VERSION "v0.0.5"

NS_ :

BS_:

BU_: LOCO_PLC Screen DCDC1 CVC Telematics PDM1

BO_ 2147545100 Debug_C: 8 CVC
 SG_ debug_C_plc_msg1F_count m31 : 48|16@1+ (1,0) [0|65535] "0"  Telematics
 SG_ debug_C_plc_msg1E_count m30 : 48|16@1+ (1,0) [0|65535] "0"  Telematics
 SG_ debug_C_plc_msg1D_count m29 : 48|16@1+ (1,0) [0|65535] "0"  Telematics
 SG_ debug_C_plc_msg1C_count m28 : 48|16@1+ (1,0) [0|65535] "0"  Telematics
 SG_ debug_C_plc_msg1B_count m27 : 48|16@1+ (1,0) [0|65535] "0"  Telematics
 SG_ debug_C_plc_msg1A_count m26 : 48|16@1+ (1,0) [0|65535] "0"  Telematics
 SG_ debug_C_plc_msg19_count m25 : 48|16@1+ (1,0) [0|65535] "0"  Telematics
 SG_ debug_C_plc_msg18_count m24 : 48|16@1+ (1,0) [0|65535] "0"  Telematics
 SG_ debug_C_plc_msg17_count m23 : 48|16@1+ (1,0) [0|65535] "0"  Telematics
 SG_ debug_C_plc_msg16_count m22 : 48|16@1+ (1,0) [0|65535] "0"  Telematics
 SG_ debug_C_plc_msg15_count m21 : 48|16@1+ (1,0) [0|65535] "0"  Telematics
 SG_ debug_C_plc_msg14_count m20 : 48|16@1+ (1,0) [0|65535] "0"  Telematics
 SG_ debug_C_plc_msg13_count m19 : 48|16@1+ (1,0) [0|65535] "0"  Telematics
 SG_ debug_C_plc_msg12_count m18 : 48|16@1+ (1,0) [0|65535] "0"  Telematics
 SG_ debug_C_plc_msg11_count m17 : 48|16@1+ (1,0) [0|65535] "0"  Telematics
 SG_ debug_C_plc_msg10_count m16 : 48|16@1+ (1,0) [0|65535] "0"  Telematics
 SG_ debug_C_plc_msg0F_count m15 : 48|16@1+ (1,0) [0|65535] "0"  Telematics
 SG_ debug_C_plc_msg0E_count m14 : 48|16@1+ (1,0) [0|65535] "0"  Telematics
 SG_ debug_C_plc_msg0D_count m13 : 48|16@1+ (1,0) [0|65535] "0"  Telematics
 SG_ debug_C_plc_msg0C_count m12 : 48|16@1+ (1,0) [0|65535] "0"  Telematics
 SG_ debug_C_plc_msg0B_count m11 : 48|16@1+ (1,0) [0|65535] "0"  Telematics
 SG_ debug_C_plc_msg0A_count m10 : 48|16@1+ (1,0) [0|65535] "0"  Telematics
 SG_ debug_C_plc_msg09_count m9 : 48|16@1+ (1,0) [0|65535] "0"  Telematics
 SG_ debug_C_plc_msg08_count m8 : 48|16@1+ (1,0) [0|65535] "0"  Telematics
 SG_ debug_C_plc_msg07_count m7 : 48|16@1+ (1,0) [0|65535] "0"  Telematics
 SG_ debug_C_plc_msg06_count m6 : 48|16@1+ (1,0) [0|65535] "0"  Telematics
 SG_ debug_C_plc_msg05_count m5 : 48|16@1+ (1,0) [0|65535] "0"  Telematics
 SG_ debug_C_plc_msg04_count m4 : 48|16@1+ (1,0) [0|65535] "0"  Telematics
 SG_ debug_C_plc_msg03_count m3 : 48|16@1+ (1,0) [0|65535] "0"  Telematics
 SG_ debug_C_plc_msg02_count m2 : 48|16@1+ (1,0) [0|65535] "0"  Telematics
 SG_ debug_C_plc_msg01_count m1 : 48|16@1+ (1,0) [0|65535] "0"  Telematics
 SG_ debug_C_plc_msg00_count m0 : 48|16@1+ (1,0) [0|65535] "0"  Telematics
 SG_ debug_C_plc_msg_mult M : 0|8@1+ (1,0) [0|255] "0"  Telematics

BO_ 2147545099 Debug_B: 8 CVC
 SG_ debug_B_Voltage_Sensor : 0|16@1+ (0.01,0) [0|600] "V"  LOCO_PLC

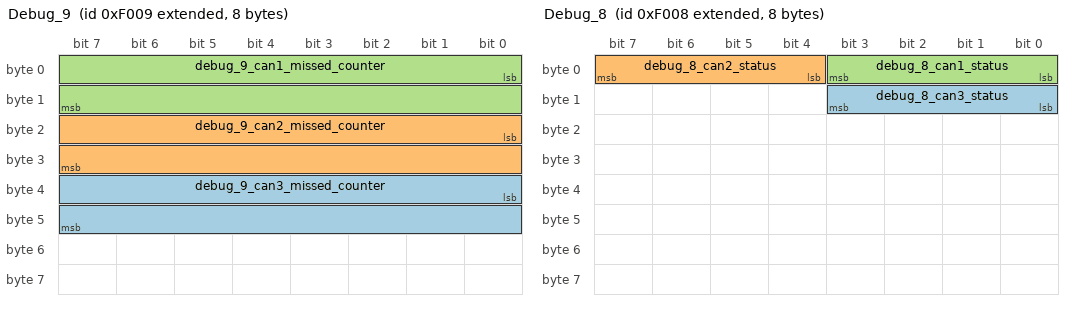
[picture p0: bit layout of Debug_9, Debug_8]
BO_ 2147545097 Debug_9: 8 CVC
 SG_ debug_9_can3_missed_counter : 32|16@1+ (1,0) [0|65535] ""  Telematics
 SG_ debug_9_can2_missed_counter : 16|16@1+ (1,0) [0|65535] ""  Telematics
 SG_ debug_9_can1_missed_counter : 0|16@1+ (1,0) [0|65535] ""  Telematics

BO_ 2147545096 Debug_8: 8 CVC
 SG_ debug_8_can3_status : 8|4@1+ (1,0) [0|15] ""  Telematics
 SG_ debug_8_can2_status : 4|4@1+ (1,0) [0|15] ""  Telematics
 SG_ debug_8_can1_status : 0|4@1+ (1,0) [0|15] ""  Telematics

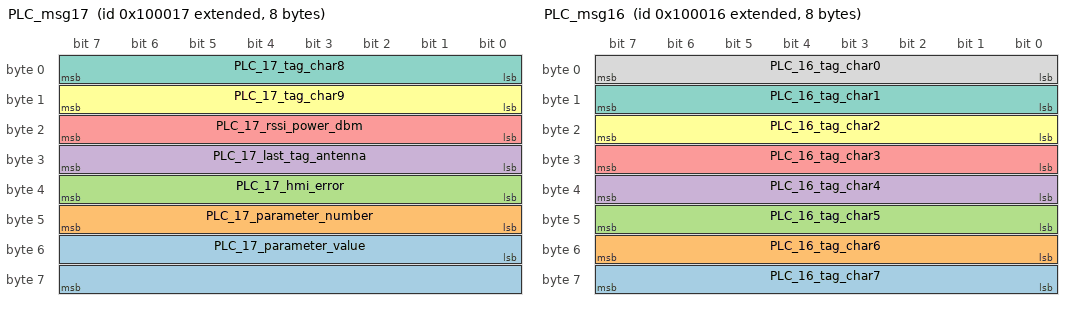
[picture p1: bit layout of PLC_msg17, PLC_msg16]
BO_ 2148532247 PLC_msg17: 8 LOCO_PLC
 SG_ PLC_17_parameter_value : 48|16@1+ (1,0) [0|255] ""  CVC
 SG_ PLC_17_parameter_number : 40|8@1+ (1,0) [0|255] ""  CVC
 SG_ PLC_17_hmi_error : 32|8@1+ (1,0) [0|255] ""  CVC
 SG_ PLC_17_last_tag_antenna : 24|8@1+ (1,0) [0|255] ""  CVC
 SG_ PLC_17_rssi_power_dbm : 16|8@1+ (1,0) [0|255] "dBm"  CVC
 SG_ PLC_17_tag_char9 : 8|8@1+ (1,0) [0|255] ""  CVC
 SG_ PLC_17_tag_char8 : 0|8@1+ (1,0) [0|255] ""  CVC

BO_ 2148532246 PLC_msg16: 8 LOCO_PLC
 SG_ PLC_16_tag_char7 : 56|8@1+ (1,0) [0|255] ""  CVC
 SG_ PLC_16_tag_char6 : 48|8@1+ (1,0) [0|255] ""  CVC
 SG_ PLC_16_tag_char5 : 40|8@1+ (1,0) [0|255] ""  CVC
 SG_ PLC_16_tag_char4 : 32|8@1+ (1,0) [0|255] ""  CVC
 SG_ PLC_16_tag_char3 : 24|8@1+ (1,0) [0|255] ""  CVC
 SG_ PLC_16_tag_char2 : 16|8@1+ (1,0) [0|255] ""  CVC
 SG_ PLC_16_tag_char1 : 8|8@1+ (1,0) [0|255] ""  CVC
 SG_ PLC_16_tag_char0 : 0|8@1+ (1,0) [0|255] ""  CVC

BO_ 2148532245 PLC_msg15: 8 LOCO_PLC
 SG_ PLC_15_unused_63 : 63|1@1+ (1,0) [0|1] ""  CVC
 SG_ PLC_15_unused_62 : 62|1@1+ (1,0) [0|1] ""  CVC
 SG_ PLC_15_unused_61 : 61|1@1+ (1,0) [0|1] ""  CVC
 SG_ PLC_15_earth_leakage : 60|1@1+ (1,0) [0|1] ""  CVC
 SG_ PLC_15_alarm_vibration_gb2 : 59|1@1+ (1,0) [0|1] ""  CVC
 SG_ PLC_15_prealarm_vibration_gb2 : 58|1@1+ (1,0) [0|1] ""  CVC
 SG_ PLC_15_alarm_vibration_gb1 : 57|1@1+ (1,0) [0|1] ""  CVC
 SG_ PLC_15_prealarm_vibration_gb1 : 56|1@1+ (1,0) [0|1] ""  CVC
 SG_ PLC_15_unused_55 : 55|1@1+ (1,0) [0|1] ""  CVC
 SG_ PLC_15_unused_54 : 54|1@1+ (1,0) [0|1] ""  CVC
 SG_ PLC_15_drive_cont_aux2 : 53|1@1+ (1,0) [0|1] ""  CVC
 SG_ PLC_15_drive_cont_2 : 52|1@1+ (1,0) [0|1] ""  CVC
 SG_ PLC_15_precharge_2 : 51|1@1+ (1,0) [0|1] ""  CVC
 SG_ PLC_15_drive_cont_aux1 : 50|1@1+ (1,0) [0|1] ""  CVC
 SG_ PLC_15_drive_cont_1 : 49|1@1+ (1,0) [0|1] ""  CVC
 SG_ PLC_15_precharge_1 : 48|1@1+ (1,0) [0|1] ""  CVC
 SG_ PLC_15_unused_47 : 47|1@1+ (1,0) [0|1] ""  CVC
 SG_ PLC_15_unused_46 : 46|1@1+ (1,0) [0|1] ""  CVC
 SG_ PLC_15_unused_45 : 45|1@1+ (1,0) [0|1] ""  CVC
 SG_ PLC_15_unused_44 : 44|1@1+ (1,0) [0|1] ""  CVC
 SG_ PLC_15_parameter_pin_ok : 43|1@1+ (1,0) [0|1] ""  CVC
 SG_ PLC_15_page_parameters : 42|1@1+ (1,0) [0|1] ""  CVC
 SG_ PLC_15_tester_pin_ok : 41|1@1+ (1,0) [0|1] ""  CVC
 SG_ PLC_15_page_tester : 40|1@1+ (1,0) [0|1] ""  CVC
 SG_ PLC_15_unused_39 : 39|1@1+ (1,0) [0|1] ""  CVC
 SG_ PLC_15_unused_38 : 38|1@1+ (1,0) [0|1] ""  CVC
 SG_ PLC_15_unused_37 : 37|1@1+ (1,0) [0|1] ""  CVC
 SG_ PLC_15_unused_36 : 36|1@1+ (1,0) [0|1] ""  CVC
 SG_ PLC_15_high_power_mode : 35|1@1+ (1,0) [0|1] ""  CVC
 SG_ PLC_15_direction_locked : 34|1@1+ (1,0) [0|1] ""  CVC
 SG_ PLC_15_direction_outbyte : 33|1@1+ (1,0) [0|1] ""  CVC
 SG_ PLC_15_direction_inbyte : 32|1@1+ (1,0) [0|1] ""  CVC
 SG_ PLC_15_unused_31 : 31|1@1+ (1,0) [0|1] ""  CVC
 SG_ PLC_15_unused_30 : 30|1@1+ (1,0) [0|1] ""  CVC
 SG_ PLC_15_unused_29 : 29|1@1+ (1,0) [0|1] ""  CVC
 SG_ PLC_15_unused_28 : 28|1@1+ (1,0) [0|1] ""  CVC
 SG_ PLC_15_unused_27 : 27|1@1+ (1,0) [0|1] ""  CVC
 SG_ PLC_15_wifi_locked : 26|1@1+ (1,0) [0|1] ""  CVC
 SG_ PLC_15_remote_connected : 25|1@1+ (1,0) [0|1] ""  CVC
 SG_ PLC_15_tandem_connected : 24|1@1+ (1,0) [0|1] ""  CVC
 SG_ PLC_15_unused_23 : 23|1@1+ (1,0) [0|1] ""  CVC
 SG_ PLC_15_unused_22 : 22|1@1+ (1,0) [0|1] ""  CVC
 SG_ PLC_15_unused_21 : 21|1@1+ (1,0) [0|1] ""  CVC
 SG_ PLC_15_unused_20 : 20|1@1+ (1,0) [0|1] ""  CVC
 SG_ PLC_15_axlebox_4 : 19|1@1+ (1,0) [0|1] ""  CVC
 SG_ PLC_15_axlebox_3 : 18|1@1+ (1,0) [0|1] ""  CVC
 SG_ PLC_15_axlebox_2 : 17|1@1+ (1,0) [0|1] ""  CVC
 SG_ PLC_15_axlebox_1 : 16|1@1+ (1,0) [0|1] ""  CVC
 SG_ PLC_15_unused_15 : 15|1@1+ (1,0) [0|1] ""  CVC
 SG_ PLC_15_unused_14 : 14|1@1+ (1,0) [0|1] ""  CVC
 SG_ PLC_15_unused_13 : 13|1@1+ (1,0) [0|1] ""  CVC
 SG_ PLC_15_unused_12 : 12|1@1+ (1,0) [0|1] ""  CVC
 SG_ PLC_15_pb_train_in_motion : 11|1@1+ (1,0) [0|1] ""  CVC
 SG_ PLC_15_deadmans_as_serv_brake : 10|1@1+ (1,0) [0|1] ""  CVC
 SG_ PLC_15_bat_disconnect_moving : 9|1@1+ (1,0) [0|1] ""  CVC
 SG_ PLC_15_bat_disconnect_stationary : 8|1@1+ (1,0) [0|1] ""  CVC
 SG_ PLC_15_train_d : 7|1@1+ (1,0) [0|1] ""  CVC
 SG_ PLC_15_train_c : 6|1@1+ (1,0) [0|1] ""  CVC
 SG_ PLC_15_train_b : 5|1@1+ (1,0) [0|1] ""  CVC
 SG_ PLC_15_train_a : 4|1@1+ (1,0) [0|1] ""  CVC
 SG_ PLC_15_single : 3|1@1+ (1,0) [0|1] ""  CVC
 SG_ PLC_15_slave : 2|1@1+ (1,0) [0|1] ""  CVC
 SG_ PLC_15_master_no_plug : 1|1@1+ (1,0) [0|1] ""  CVC
 SG_ PLC_15_master : 0|1@1+ (1,0) [0|1] ""  CVC

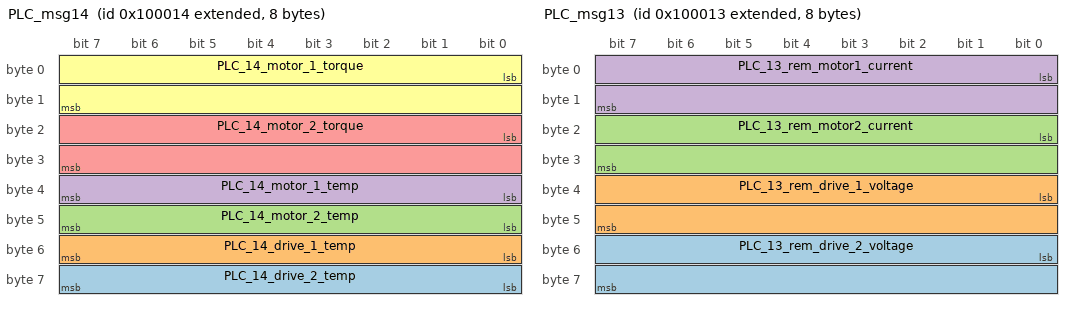
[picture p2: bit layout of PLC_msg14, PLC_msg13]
BO_ 2148532244 PLC_msg14: 8 LOCO_PLC
 SG_ PLC_14_drive_2_temp : 56|8@1+ (1,-40) [-40|210] "C"  CVC
 SG_ PLC_14_drive_1_temp : 48|8@1+ (1,-40) [-40|210] "C"  CVC
 SG_ PLC_14_motor_2_temp : 40|8@1+ (1,-40) [-40|210] "C"  CVC
 SG_ PLC_14_motor_1_temp : 32|8@1+ (1,-40) [-40|210] "C"  CVC
 SG_ PLC_14_motor_2_torque : 16|16@1+ (0.004,-125) [-125|132.02] "%"  CVC
 SG_ PLC_14_motor_1_torque : 0|16@1+ (0.004,-125) [-125|132.02] "%"  CVC

BO_ 2148532243 PLC_msg13: 8 LOCO_PLC
 SG_ PLC_13_rem_drive_2_voltage : 48|16@1+ (0.05,0) [0|3276.75] "V"  CVC
 SG_ PLC_13_rem_drive_1_voltage : 32|16@1+ (0.05,0) [0|3276.75] "V"  CVC
 SG_ PLC_13_rem_motor2_current : 16|16@1+ (0.05,-1600) [-1638.4|1638.35] "A"  CVC
 SG_ PLC_13_rem_motor1_current : 0|16@1+ (0.05,-1600) [-1638.4|1638.35] "A"  CVC

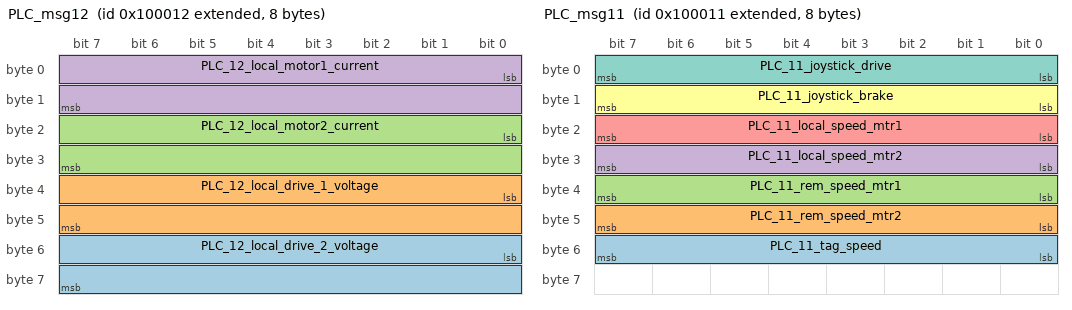
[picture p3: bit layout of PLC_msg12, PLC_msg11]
BO_ 2148532242 PLC_msg12: 8 LOCO_PLC
 SG_ PLC_12_local_drive_2_voltage : 48|16@1+ (0.05,0) [0|3276.75] "V"  CVC
 SG_ PLC_12_local_drive_1_voltage : 32|16@1+ (0.05,0) [0|3276.75] "V"  CVC
 SG_ PLC_12_local_motor2_current : 16|16@1+ (0.05,-1600) [-1638.4|1638.35] "A"  CVC
 SG_ PLC_12_local_motor1_current : 0|16@1+ (0.05,-1600) [-1638.4|1638.35] "A"  CVC

BO_ 2148532241 PLC_msg11: 8 LOCO_PLC
 SG_ PLC_11_tag_speed : 48|8@1+ (0.1,0) [0|25.5] "km/h"  CVC
 SG_ PLC_11_rem_speed_mtr2 : 40|8@1+ (0.1,0) [0|25.5] "km/h" Vector__XXX
 SG_ PLC_11_rem_speed_mtr1 : 32|8@1+ (0.1,0) [0|25.5] "km/h" Vector__XXX
 SG_ PLC_11_local_speed_mtr2 : 24|8@1+ (0.1,0) [0|25.5] "km/h"  CVC
 SG_ PLC_11_local_speed_mtr1 : 16|8@1+ (0.1,0) [0|25.5] "km/h"  CVC
 SG_ PLC_11_joystick_brake : 8|8@1+ (1,0) [0|255] "%"  CVC
 SG_ PLC_11_joystick_drive : 0|8@1+ (1,0) [0|255] "%"  CVC

BO_ 2148532240 PLC_msg10: 8 LOCO_PLC
 SG_ PLC_10_unused_7 : 56|8@1+ (1,0) [0|255] ""  CVC
 SG_ PLC_10_unused_6 : 54|2@1+ (1,0) [0|3] ""  CVC
 SG_ PLC_10_taillights_rear_rem : 53|1@1+ (1,0) [0|1] ""  CVC
 SG_ PLC_10_headlights_rear_rem : 52|1@1+ (1,0) [0|1] ""  CVC
 SG_ PLC_10_headlights_front_rem : 51|1@1+ (1,0) [0|1] ""  CVC
 SG_ PLC_10_taillights_rear_local : 50|1@1+ (1,0) [0|1] ""  CVC
 SG_ PLC_10_headlights_rear_local : 49|1@1+ (1,0) [0|1] ""  CVC
 SG_ PLC_10_headlights_front_local : 48|1@1+ (1,0) [0|1] ""  CVC
 SG_ PLC_10_unused_4 : 47|1@1+ (1,0) [0|1] ""  CVC
 SG_ PLC_10_remote_fire_pb : 46|1@1+ (1,0) [0|1] ""  CVC
 SG_ PLC_10_remote_fire_shutdown : 45|1@1+ (1,0) [0|1] ""  CVC
 SG_ PLC_10_local_fire_sys_shutdown : 44|1@1+ (1,0) [0|1] ""  CVC
 SG_ PLC_10_tandem_new_tag_braking : 43|1@1+ (1,0) [0|1] ""  CVC
 SG_ PLC_10_tandem_rem_batt_rtd : 42|1@1+ (1,0) [0|1] ""  CVC
 SG_ PLC_10_tandem_em_pb : 41|1@1+ (1,0) [0|1] ""  CVC
 SG_ PLC_10_tandem_esr : 40|1@1+ (1,0) [0|1] ""  CVC
 SG_ PLC_10_battery_ready_estop : 39|1@1+ (1,0) [0|1] ""  CVC
 SG_ PLC_10_tag_estop : 38|1@1+ (1,0) [0|1] ""  CVC
 SG_ PLC_10_overspeed : 37|1@1+ (1,0) [0|1] ""  CVC
 SG_ PLC_10_estop_console : 36|1@1+ (1,0) [0|1] ""  CVC
 SG_ PLC_10_estop_btn_remote : 35|1@1+ (1,0) [0|1] ""  CVC
 SG_ PLC_10_estop_relay_remote : 34|1@1+ (1,0) [0|1] ""  CVC
 SG_ PLC_10_estop_btn_local : 33|1@1+ (1,0) [0|1] ""  CVC
 SG_ PLC_10_estop_relay_local : 32|1@1+ (1,0) [0|1] ""  CVC
 SG_ PLC_10_unused_3 : 31|1@1+ (1,0) [0|1] ""  CVC
 SG_ PLC_10_slave : 30|1@1+ (1,0) [0|1] ""  CVC
 SG_ PLC_10_master_no_plug : 29|1@1+ (1,0) [0|1] ""  CVC
 SG_ PLC_10_master : 28|1@1+ (1,0) [0|1] ""  CVC
 SG_ PLC_10_seatbelt_remote : 27|1@1+ (1,0) [0|1] ""  CVC
 SG_ PLC_10_passenger_remote : 26|1@1+ (1,0) [0|1] ""  CVC
 SG_ PLC_10_seatbelt_local : 25|1@1+ (1,0) [0|1] ""  CVC
 SG_ PLC_10_driver_in_seat_local : 24|1@1+ (1,0) [0|1] ""  CVC
 SG_ PLC_10_pb_sw_in_motion : 23|1@1+ (1,0) [0|1] ""  CVC
 SG_ PLC_10_pb_2_remote : 22|1@1+ (1,0) [0|1] ""  CVC
 SG_ PLC_10_pb_1_remote : 21|1@1+ (1,0) [0|1] ""  CVC
 SG_ PLC_10_pb_relay_remote : 20|1@1+ (1,0) [0|1] ""  CVC
 SG_ PLC_10_pb_2_local : 19|1@1+ (1,0) [0|1] ""  CVC
 SG_ PLC_10_pb_1_local : 18|1@1+ (1,0) [0|1] ""  CVC
 SG_ PLC_10_pb_relay_local : 17|1@1+ (1,0) [0|1] ""  CVC
 SG_ PLC_10_pb_hold : 16|1@1+ (1,0) [0|1] ""  CVC
 SG_ PLC_10_explosives : 15|1@1+ (1,0) [0|1] ""  CVC
 SG_ PLC_10_key_full : 14|1@1+ (1,0) [0|1] ""  CVC
 SG_ PLC_10_key_neutral : 13|1@1+ (1,0) [0|1] ""  CVC
 SG_ PLC_10_key_semi : 12|1@1+ (1,0) [0|1] ""  CVC
 SG_ PLC_10_loco_rev : 11|1@1+ (1,0) [0|1] ""  CVC
 SG_ PLC_10_loco_fwd : 10|1@1+ (1,0) [0|1] ""  CVC
 SG_ PLC_10_rev_dir_sw : 9|1@1+ (1,0) [0|1] ""  CVC
 SG_ PLC_10_fwd_dir_sw : 8|1@1+ (1,0) [0|1] ""  CVC
 SG_ PLC_10_horn_console : 7|1@1+ (1,0) [0|1] ""  CVC
 SG_ PLC_10_horn_remote : 6|1@1+ (1,0) [0|1] ""  CVC
 SG_ PLC_10_horn_local : 5|1@1+ (1,0) [0|1] ""  CVC
 SG_ PLC_10_deadman_timer : 4|1@1+ (1,0) [0|1] ""  CVC
 SG_ PLC_10_deadman_trigger : 3|1@1+ (1,0) [0|1] ""  CVC
 SG_ PLC_10_neutral : 2|1@1+ (1,0) [0|1] ""  CVC
 SG_ PLC_10_brake : 1|1@1+ (1,0) [0|1] ""  CVC
 SG_ PLC_10_drive : 0|1@1+ (1,0) [0|1] ""  CVC

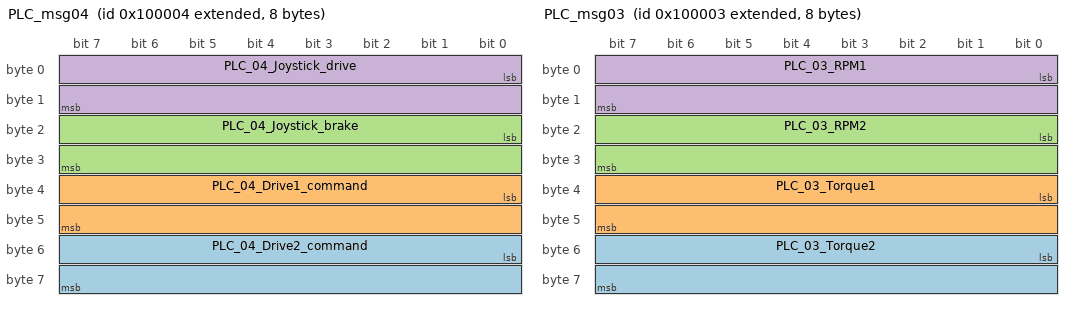
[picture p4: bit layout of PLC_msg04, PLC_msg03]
BO_ 2148532228 PLC_msg04: 8 LOCO_PLC
 SG_ PLC_04_Drive2_command : 48|16@1+ (0.08,-2500) [-2500|2742.8] "Nm"  CVC
 SG_ PLC_04_Drive1_command : 32|16@1+ (0.08,-2500) [-2500|2742.8] "Nm"  CVC
 SG_ PLC_04_Joystick_brake : 16|16@1+ (0.004,0) [0|262.14] "%"  CVC
 SG_ PLC_04_Joystick_drive : 0|16@1+ (0.004,0) [0|262.14] "%"  CVC

BO_ 2148532227 PLC_msg03: 8 LOCO_PLC
 SG_ PLC_03_Torque2 : 48|16@1+ (0.08,-2500) [-2500|2742.8] "Nm"  CVC
 SG_ PLC_03_Torque1 : 32|16@1+ (0.08,-2500) [-2500|2742.8] "Nm"  CVC
 SG_ PLC_03_RPM2 : 16|16@1+ (0.072,-2250) [-2250|2468.52] "RPM"  CVC
 SG_ PLC_03_RPM1 : 0|16@1+ (0.072,-2250) [-2250|2468.52] "RPM"  CVC

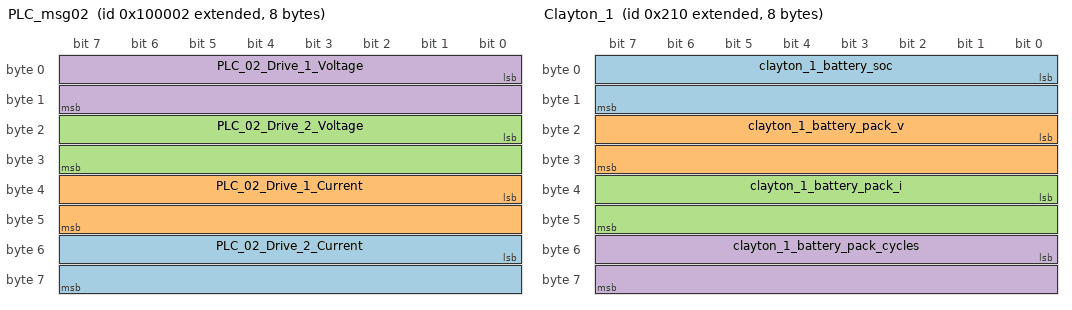
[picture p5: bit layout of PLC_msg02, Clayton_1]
BO_ 2148532226 PLC_msg02: 8 LOCO_PLC
 SG_ PLC_02_Drive_2_Current : 48|16@1+ (0.05,-1600) [-1600|1600] "A"  CVC
 SG_ PLC_02_Drive_1_Current : 32|16@1+ (0.05,-1600) [-1600|1600] "A"  CVC
 SG_ PLC_02_Drive_2_Voltage : 16|16@1+ (0.05,0) [0|3276.75] "V"  CVC
 SG_ PLC_02_Drive_1_Voltage : 0|16@1+ (0.05,0) [0|3276.75] "V"  CVC

BO_ 2148532225 PLC_msg01: 8 LOCO_PLC
 SG_ PLC_01_fire_suppression : 1|1@1+ (1,0) [0|1] ""  CVC
 SG_ PLC_01_earth_leakage : 0|1@1+ (1,0) [0|1] ""  CVC

BO_ 2148532224 PLC_msg00: 8 LOCO_PLC
 SG_ PLC_00_runtime : 0|32@1+ (0.000277777777777778,0) [0|1193046.47083333] "hr"  CVC
 SG_ PLC_00_distance : 32|32@1+ (2.77777777777778E-005,0) [0|119304.647083333] "km"  CVC

BO_ 2149273602 BMS_MSG2: 8 CVC
 SG_ BMS6_pack_soc m6 : 8|8@1+ (0.5,0) [0|127.5] "%"  LOCO_PLC
 SG_ BMS6_pack_inst_v m6 : 32|16@1+ (0.1,0) [0|6553.5] ""  LOCO_PLC
 SG_ BMS6_pack_cycles m6 : 48|16@1+ (1,0) [0|65535] ""  LOCO_PLC
 SG_ BMS6_pack_current m6 : 16|16@1- (0.1,0) [-3276.8|3276.7] "A"  LOCO_PLC
 SG_ BMS5_pack_soc m5 : 8|8@1+ (0.5,0) [0|127.5] "%"  LOCO_PLC
 SG_ BMS5_pack_inst_v m5 : 32|16@1+ (0.1,0) [0|6553.5] ""  LOCO_PLC
 SG_ BMS5_pack_cycles m5 : 48|16@1+ (1,0) [0|65535] ""  LOCO_PLC
 SG_ BMS5_pack_current m5 : 16|16@1- (0.1,0) [-3276.8|3276.7] "A"  LOCO_PLC
 SG_ BMS4_pack_soc m4 : 8|8@1+ (0.5,0) [0|127.5] "%"  LOCO_PLC
 SG_ BMS4_pack_inst_v m4 : 32|16@1+ (0.1,0) [0|6553.5] ""  LOCO_PLC
 SG_ BMS4_pack_cycles m4 : 48|16@1+ (1,0) [0|65535] ""  LOCO_PLC
 SG_ BMS4_pack_current m4 : 16|16@1- (0.1,0) [-3276.8|3276.7] "A"  LOCO_PLC
 SG_ BMS3_pack_inst_v m3 : 32|16@1+ (0.1,0) [0|6553.5] ""  LOCO_PLC
 SG_ BMS3_pack_cycles m3 : 48|16@1+ (1,0) [0|65535] ""  LOCO_PLC
 SG_ BMS3_pack_current m3 : 16|16@1- (0.1,0) [-3276.8|3276.7] "A"  LOCO_PLC
 SG_ BMS3_pack_soc m3 : 8|8@1+ (0.5,0) [0|127.5] "%"  LOCO_PLC
 SG_ BMS2_pack_inst_v m2 : 32|16@1+ (0.1,0) [0|6553.5] ""  LOCO_PLC
 SG_ BMS2_pack_cycles m2 : 48|16@1+ (1,0) [0|65535] ""  LOCO_PLC
 SG_ BMS2_pack_current m2 : 16|16@1- (0.1,0) [-3276.8|3276.7] "A"  LOCO_PLC
 SG_ BMS2_pack_soc m2 : 8|8@1+ (0.5,0) [0|127.5] "%"  LOCO_PLC
 SG_ BMS1_pack_soc m1 : 8|8@1+ (0.5,0) [0|127.5] "%"  LOCO_PLC
 SG_ BMS1_pack_inst_v m1 : 32|16@1+ (0.1,0) [0|6553.5] ""  LOCO_PLC
 SG_ BMS1_pack_cycles m1 : 48|16@1+ (1,0) [0|65535] ""  LOCO_PLC
 SG_ BMS1_pack_current m1 : 16|16@1- (0.1,0) [-3276.8|3276.7] "A"  LOCO_PLC
 SG_ BMS_MSG2_idx M : 0|8@1+ (1,0) [1|6] "ID"  LOCO_PLC

BO_ 2147484176 Clayton_1: 8 CVC
 SG_ clayton_1_battery_soc : 0|16@1+ (0.1,0) [0|6553.5] "%"  LOCO_PLC
 SG_ clayton_1_battery_pack_v : 16|16@1+ (0.1,0) [0|6553.5] "V"  LOCO_PLC
 SG_ clayton_1_battery_pack_i : 32|16@1- (0.1,0) [-3276.8|3276.7] "A"  LOCO_PLC
 SG_ clayton_1_battery_pack_cycles : 48|16@1+ (1,0) [0|65535] ""  LOCO_PLC

BO_ 2147484177 Clayton_2: 8 CVC
 SG_ clayton_2_unused_2 : 45|3@1+ (1,0) [0|1] ""  LOCO_PLC
 SG_ clayton_2_charger_coolant_level : 48|16@1+ (1,0) [0|65535] "%"  LOCO_PLC
 SG_ clayton_2_unused_1 : 39|1@1+ (1,0) [0|1] ""  LOCO_PLC
 SG_ clayton_2_limp_mode : 42|1@1+ (1,0) [0|1] ""  LOCO_PLC
 SG_ clayton_2_general_warning : 44|1@1+ (1,0) [0|1] ""  LOCO_PLC
 SG_ clayton_2_current_imbal_warning : 43|1@1+ (1,0) [0|1] ""  LOCO_PLC
 SG_ clayton_2_current_imbal_error : 38|1@1+ (1,0) [0|1] ""  LOCO_PLC
 SG_ clayton_2_coolant_low : 40|1@1+ (1,0) [0|1] ""  LOCO_PLC
 SG_ clayton_2_bms_warning : 41|1@1+ (1,0) [0|1] ""  LOCO_PLC
 SG_ clayton_2_pump_failure : 32|1@1+ (1,0) [0|1] ""  LOCO_PLC
 SG_ clayton_2_pump_current_warning : 30|1@1+ (1,0) [0|1] ""  LOCO_PLC
 SG_ clayton_2_fan_failure : 33|1@1+ (1,0) [0|1] ""  LOCO_PLC
 SG_ clayton_2_fan_current_warning : 31|1@1+ (1,0) [0|1] ""  LOCO_PLC
 SG_ clayton_2_critical_fault : 37|1@1+ (1,0) [0|1] ""  LOCO_PLC
 SG_ clayton_2_coolant_sensor_failure : 35|1@1+ (1,0) [0|1] ""  LOCO_PLC
 SG_ clayton_2_cell_delta_problem : 28|1@1+ (1,0) [0|1] ""  LOCO_PLC
 SG_ clayton_2_bms_temp_warning : 29|1@1+ (1,0) [0|1] ""  LOCO_PLC
 SG_ clayton_2_bms_error : 36|1@1+ (1,0) [0|1] ""  LOCO_PLC
 SG_ clayton_2_battery_under_temp : 34|1@1+ (1,0) [0|1] ""  LOCO_PLC
 SG_ clayton_2_warm_batt_temp : 25|1@1+ (1,0) [0|1] ""  LOCO_PLC
 SG_ clayton_2_uvp : 18|1@1+ (1,0) [0|1] ""  LOCO_PLC
 SG_ clayton_2_ucp : 20|1@1+ (1,0) [0|1] ""  LOCO_PLC
 SG_ clayton_2_subpacks_connected : 8|8@1+ (1,0) [0|255] ""  LOCO_PLC
 SG_ clayton_2_subpack_sync : 24|1@1+ (1,0) [0|1] ""  LOCO_PLC
 SG_ clayton_2_ovp : 17|1@1+ (1,0) [0|1] ""  LOCO_PLC
 SG_ clayton_2_ocp : 19|1@1+ (1,0) [0|1] ""  LOCO_PLC
 SG_ clayton_2_hvil_loop_broken : 16|1@1+ (1,0) [0|1] ""  LOCO_PLC
 SG_ clayton_2_hv_iso_fault : 21|1@1+ (1,0) [0|1] ""  LOCO_PLC
 SG_ clayton_2_estop_pushed : 27|1@1+ (1,0) [0|1] ""  LOCO_PLC
 SG_ clayton_2_contactor_failure : 22|1@1+ (1,0) [0|1] ""  LOCO_PLC
 SG_ clayton_2_battery_status : 0|8@1+ (1,0) [0|255] ""  LOCO_PLC
 SG_ clayton_2_battery_overtemp : 23|1@1+ (1,0) [0|1] ""  LOCO_PLC
 SG_ clayton_2_batt_too_cold : 26|1@1+ (1,0) [0|1] ""  LOCO_PLC

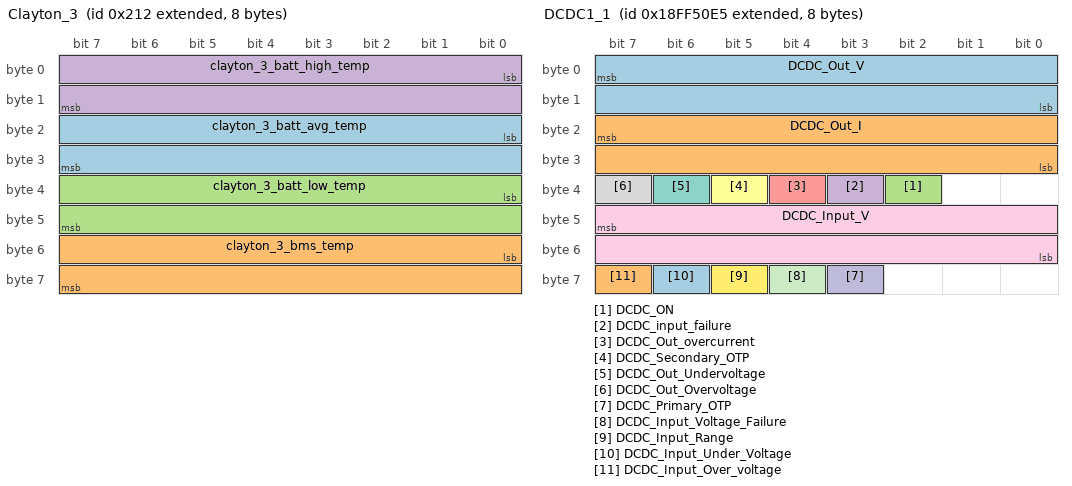
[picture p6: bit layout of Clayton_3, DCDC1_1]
BO_ 2147484178 Clayton_3: 8 CVC
 SG_ clayton_3_batt_avg_temp : 16|16@1- (1,0) [-32768|32767] "C"  LOCO_PLC
 SG_ clayton_3_bms_temp : 48|16@1- (1,0) [-32768|32767] "C"  LOCO_PLC
 SG_ clayton_3_batt_low_temp : 32|16@1- (1,0) [-32768|32767] "C"  LOCO_PLC
 SG_ clayton_3_batt_high_temp : 0|16@1- (1,0) [-32768|32767] "C"  LOCO_PLC

BO_ 2498698769 PDM_cmd: 8 CVC
 SG_ PDM_MULTIP_1 M : 0|8@1+ (1,0) [0|255] ""  PDM1
 SG_ PDM000_Output_Channel m0M : 8|8@1+ (1,0) [0|255] ""  PDM1
 SG_ PDM000_SS_Step_DO01 m1 : 16|8@1+ (1,0) [0|255] ""  PDM1
 SG_ PDM000_M_L_DO01 m1 : 24|8@1+ (1,0) [0|255] ""  PDM1
 SG_ PDM000_Loss_of_COMM_DO01 m1 : 32|8@1+ (1,0) [0|255] ""  PDM1
 SG_ PDM000_POR_command_DO01 m1 : 48|5@1- (6.25,0) [0|93] ""  PDM1
 SG_ PDM000_POR_En_DO01 m1 : 53|1@1+ (1,0) [0|1] ""  PDM1
 SG_ PDM000_Command_type_DO01 m1 : 54|1@1+ (1,0) [0|1] ""  PDM1
 SG_ PDM000_Motor_braking_DO01 m1 : 55|1@1+ (1,0) [0|1] ""  PDM1
 SG_ PDM000_LSC_DO01 m1 : 56|4@1+ (1,0) [0|15] ""  PDM1
 SG_ PDM000_Calib_time_DO01 m1 : 60|2@1+ (1,0) [0|3] ""  PDM1
 SG_ PDM000_Response_DO01 m1 : 62|2@1+ (1,0) [0|3] ""  PDM1
 SG_ PDM000_SS_Step_DO02 m2 : 16|8@1+ (1,0) [0|255] ""  PDM1
 SG_ PDM000_M_L_DO02 m2 : 24|8@1+ (1,0) [0|255] ""  PDM1
 SG_ PDM000_Loss_of_COMM_DO02 m2 : 32|8@1+ (1,0) [0|255] ""  PDM1
 SG_ PDM000_POR_command_DO02 m2 : 48|5@1- (6.25,0) [0|93] ""  PDM1
 SG_ PDM000_POR_En_DO02 m2 : 53|1@1+ (1,0) [0|1] ""  PDM1
 SG_ PDM000_Command_type_DO02 m2 : 54|1@1+ (1,0) [0|1] ""  PDM1
 SG_ PDM000_Motor_braking_DO02 m2 : 55|1@1+ (1,0) [0|1] ""  PDM1
 SG_ PDM000_LSC_DO02 m2 : 56|4@1+ (1,0) [0|15] ""  PDM1
 SG_ PDM000_Calib_time_DO02 m2 : 60|2@1+ (1,0) [0|3] ""  PDM1
 SG_ PDM000_Response_DO02 m2 : 62|2@1+ (1,0) [0|3] ""  PDM1
 SG_ PDM000_SS_Step_DO03 m3 : 16|8@1+ (1,0) [0|255] ""  PDM1
 SG_ PDM000_M_L_DO03 m3 : 24|8@1+ (1,0) [0|255] ""  PDM1
 SG_ PDM000_Loss_of_COMM_DO03 m3 : 32|8@1+ (1,0) [0|255] ""  PDM1
 SG_ PDM000_POR_command_DO03 m3 : 48|5@1- (6.25,0) [0|93] ""  PDM1
 SG_ PDM000_POR_En_DO03 m3 : 53|1@1+ (1,0) [0|1] ""  PDM1
 SG_ PDM000_Command_type_DO03 m3 : 54|1@1+ (1,0) [0|1] ""  PDM1
 SG_ PDM000_Motor_braking_DO03 m3 : 55|1@1+ (1,0) [0|1] ""  PDM1
 SG_ PDM000_LSC_DO03 m3 : 56|4@1+ (1,0) [0|15] ""  PDM1
 SG_ PDM000_Calib_time_DO03 m3 : 60|2@1+ (1,0) [0|3] ""  PDM1
 SG_ PDM000_Response_DO03 m3 : 62|2@1+ (1,0) [0|3] ""  PDM1
 SG_ PDM000_SS_Step_DO04 m4 : 16|8@1+ (1,0) [0|255] ""  PDM1
 SG_ PDM000_M_L_DO04 m4 : 24|8@1+ (1,0) [0|255] ""  PDM1
 SG_ PDM000_Loss_of_COMM_DO04 m4 : 32|8@1+ (1,0) [0|255] ""  PDM1
 SG_ PDM000_POR_command_DO04 m4 : 48|5@1- (6.25,0) [0|93] ""  PDM1
 SG_ PDM000_POR_En_DO04 m4 : 53|1@1+ (1,0) [0|1] ""  PDM1
 SG_ PDM000_Command_type_DO04 m4 : 54|1@1+ (1,0) [0|1] ""  PDM1
 SG_ PDM000_Motor_braking_DO04 m4 : 55|1@1+ (1,0) [0|1] ""  PDM1
 SG_ PDM000_LSC_DO04 m4 : 56|4@1+ (1,0) [0|15] ""  PDM1
 SG_ PDM000_Calib_time_DO04 m4 : 60|2@1+ (1,0) [0|3] ""  PDM1
 SG_ PDM000_Response_DO04 m4 : 62|2@1+ (1,0) [0|3] ""  PDM1
 SG_ PDM000_SS_Step_DO05 m5 : 16|8@1+ (1,0) [0|255] ""  PDM1
 SG_ PDM000_M_L_DO05 m5 : 24|8@1+ (1,0) [0|255] ""  PDM1
 SG_ PDM000_Loss_of_COMM_DO05 m5 : 32|8@1+ (1,0) [0|255] ""  PDM1
 SG_ PDM000_POR_command_DO05 m5 : 48|5@1- (6.25,0) [0|93] ""  PDM1
 SG_ PDM000_POR_En_DO05 m5 : 53|1@1+ (1,0) [0|1] ""  PDM1
 SG_ PDM000_Command_type_DO05 m5 : 54|1@1+ (1,0) [0|1] ""  PDM1
 SG_ PDM000_Motor_braking_DO05 m5 : 55|1@1+ (1,0) [0|1] ""  PDM1
 SG_ PDM000_LSC_DO05 m5 : 56|4@1+ (1,0) [0|15] ""  PDM1
 SG_ PDM000_Calib_time_DO05 m5 : 60|2@1+ (1,0) [0|3] ""  PDM1
 SG_ PDM000_Response_DO05 m5 : 62|2@1+ (1,0) [0|3] ""  PDM1
 SG_ PDM000_SS_Step_DO06 m6 : 16|8@1+ (1,0) [0|255] ""  PDM1
 SG_ PDM000_M_L_DO06 m6 : 24|8@1+ (1,0) [0|255] ""  PDM1
 SG_ PDM000_Loss_of_COMM_DO06 m6 : 32|8@1+ (1,0) [0|255] ""  PDM1
 SG_ PDM000_POR_command_DO06 m6 : 48|5@1- (6.25,0) [0|93] ""  PDM1
 SG_ PDM000_POR_En_DO06 m6 : 53|1@1+ (1,0) [0|1] ""  PDM1
 SG_ PDM000_Command_type_DO06 m6 : 54|1@1+ (1,0) [0|1] ""  PDM1
 SG_ PDM000_Motor_braking_DO06 m6 : 55|1@1+ (1,0) [0|1] ""  PDM1
 SG_ PDM000_LSC_DO06 m6 : 56|4@1+ (1,0) [0|15] ""  PDM1
 SG_ PDM000_Calib_time_DO06 m6 : 60|2@1+ (1,0) [0|3] ""  PDM1
 SG_ PDM000_Response_DO06 m6 : 62|2@1+ (1,0) [0|3] ""  PDM1
 SG_ PDM000_SS_Step_DO07 m7 : 16|8@1+ (1,0) [0|255] ""  PDM1
 SG_ PDM000_M_L_DO07 m7 : 24|8@1+ (1,0) [0|255] ""  PDM1
 SG_ PDM000_Loss_of_COMM_DO07 m7 : 32|8@1+ (1,0) [0|255] ""  PDM1
 SG_ PDM000_POR_command_DO07 m7 : 48|5@1- (6.25,0) [0|93] ""  PDM1
 SG_ PDM000_POR_En_DO07 m7 : 53|1@1+ (1,0) [0|1] ""  PDM1
 SG_ PDM000_Command_type_DO07 m7 : 54|1@1+ (1,0) [0|1] ""  PDM1
 SG_ PDM000_Motor_braking_DO07 m7 : 55|1@1+ (1,0) [0|1] ""  PDM1
 SG_ PDM000_LSC_DO07 m7 : 56|4@1+ (1,0) [0|15] ""  PDM1
 SG_ PDM000_Calib_time_DO07 m7 : 60|2@1+ (1,0) [0|3] ""  PDM1
 SG_ PDM000_Response_DO07 m7 : 62|2@1+ (1,0) [0|3] ""  PDM1
 SG_ PDM000_SS_Step_DO08 m8 : 16|8@1+ (1,0) [0|255] ""  PDM1
 SG_ PDM000_M_L_DO08 m8 : 24|8@1+ (1,0) [0|255] ""  PDM1
 SG_ PDM000_Loss_of_COMM_DO08 m8 : 32|8@1+ (1,0) [0|255] ""  PDM1
 SG_ PDM000_POR_command_DO08 m8 : 48|5@1- (6.25,0) [0|93] ""  PDM1
 SG_ PDM000_POR_En_DO08 m8 : 53|1@1+ (1,0) [0|1] ""  PDM1
 SG_ PDM000_Command_type_DO08 m8 : 54|1@1+ (1,0) [0|1] ""  PDM1
 SG_ PDM000_Motor_braking_DO08 m8 : 55|1@1+ (1,0) [0|1] ""  PDM1
 SG_ PDM000_LSC_DO08 m8 : 56|4@1+ (1,0) [0|15] ""  PDM1
 SG_ PDM000_Calib_time_DO08 m8 : 60|2@1+ (1,0) [0|3] ""  PDM1
 SG_ PDM000_Response_DO08 m8 : 62|2@1+ (1,0) [0|3] ""  PDM1
 SG_ PDM000_SS_Step_DO09 m9 : 16|8@1+ (1,0) [0|255] ""  PDM1
 SG_ PDM000_M_L_DO09 m9 : 24|8@1+ (1,0) [0|255] ""  PDM1
 SG_ PDM000_Loss_of_COMM_DO09 m9 : 32|8@1+ (1,0) [0|255] ""  PDM1
 SG_ PDM000_POR_command_DO09 m9 : 48|5@1- (6.25,0) [0|93] ""  PDM1
 SG_ PDM000_POR_En_DO09 m9 : 53|1@1+ (1,0) [0|1] ""  PDM1
 SG_ PDM000_Command_type_DO09 m9 : 54|1@1+ (1,0) [0|1] ""  PDM1
 SG_ PDM000_Motor_braking_DO09 m9 : 55|1@1+ (1,0) [0|1] ""  PDM1
 SG_ PDM000_LSC_DO09 m9 : 56|4@1+ (1,0) [0|15] ""  PDM1
 SG_ PDM000_Calib_time_DO09 m9 : 60|2@1+ (1,0) [0|3] ""  PDM1
 SG_ PDM000_Response_DO09 m9 : 62|2@1+ (1,0) [0|3] ""  PDM1
 SG_ PDM000_SS_Step_DO10 m10 : 16|8@1+ (1,0) [0|255] ""  PDM1
 SG_ PDM000_M_L_DO10 m10 : 24|8@1+ (1,0) [0|255] ""  PDM1
 SG_ PDM000_Loss_of_COMM_DO10 m10 : 32|8@1+ (1,0) [0|255] ""  PDM1
 SG_ PDM000_POR_command_DO10 m10 : 48|5@1- (6.25,0) [0|93] ""  PDM1
 SG_ PDM000_POR_En_DO10 m10 : 53|1@1+ (1,0) [0|1] ""  PDM1
 SG_ PDM000_Command_type_DO10 m10 : 54|1@1+ (1,0) [0|1] ""  PDM1
 SG_ PDM000_Motor_braking_DO10 m10 : 55|1@1+ (1,0) [0|1] ""  PDM1
 SG_ PDM000_LSC_DO10 m10 : 56|4@1+ (1,0) [0|15] ""  PDM1
 SG_ PDM000_Calib_time_DO10 m10 : 60|2@1+ (1,0) [0|3] ""  PDM1
 SG_ PDM000_Response_DO10 m10 : 62|2@1+ (1,0) [0|3] ""  PDM1
 SG_ PDM000_SS_Step_DO11 m11 : 16|8@1+ (1,0) [0|255] ""  PDM1
 SG_ PDM000_M_L_DO11 m11 : 24|8@1+ (1,0) [0|255] ""  PDM1
 SG_ PDM000_Loss_of_COMM_DO11 m11 : 32|8@1+ (1,0) [0|255] ""  PDM1
 SG_ PDM000_POR_command_DO11 m11 : 48|5@1- (6.25,0) [0|93] ""  PDM1
 SG_ PDM000_POR_En_DO11 m11 : 53|1@1+ (1,0) [0|1] ""  PDM1
 SG_ PDM000_Command_type_DO11 m11 : 54|1@1+ (1,0) [0|1] ""  PDM1
 SG_ PDM000_Motor_braking_DO11 m11 : 55|1@1+ (1,0) [0|1] ""  PDM1
 SG_ PDM000_LSC_DO11 m11 : 56|4@1+ (1,0) [0|15] ""  PDM1
 SG_ PDM000_Calib_time_DO11 m11 : 60|2@1+ (1,0) [0|3] ""  PDM1
 SG_ PDM000_Response_DO11 m11 : 62|2@1+ (1,0) [0|3] ""  PDM1
 SG_ PDM000_SS_Step_DO12 m12 : 16|8@1+ (1,0) [0|255] ""  PDM1
 SG_ PDM000_M_L_DO12 m12 : 24|8@1+ (1,0) [0|255] ""  PDM1
 SG_ PDM000_Loss_of_COMM_DO12 m12 : 32|8@1+ (1,0) [0|255] ""  PDM1
 SG_ PDM000_POR_command_DO12 m12 : 48|5@1- (6.25,0) [0|93] ""  PDM1
 SG_ PDM000_POR_En_DO12 m12 : 53|1@1+ (1,0) [0|1] ""  PDM1
 SG_ PDM000_Command_type_DO12 m12 : 54|1@1+ (1,0) [0|1] ""  PDM1
 SG_ PDM000_Motor_braking_DO12 m12 : 55|1@1+ (1,0) [0|1] ""  PDM1
 SG_ PDM000_LSC_DO12 m12 : 56|4@1+ (1,0) [0|15] ""  PDM1
 SG_ PDM000_Calib_time_DO12 m12 : 60|2@1+ (1,0) [0|3] ""  PDM1
 SG_ PDM000_Response_DO12 m12 : 62|2@1+ (1,0) [0|3] ""  PDM1
 SG_ PDM004_CMD_DO01_PWM m4 : 8|8@1- (0.78125,0) [-100|100] "%"  PDM1
 SG_ PDM004_CMD_DO02_PWM m4 : 16|8@1- (0.78125,0) [-100|100] "%"  PDM1
 SG_ PDM004_CMD_DO03_PWM m4 : 24|8@1- (0.78125,0) [-100|100] "%"  PDM1
 SG_ PDM004_CMD_DO04_PWM m4 : 32|8@1- (0.78125,0) [-100|100] "%"  PDM1
 SG_ PDM004_CMD_DO05_PWM m4 : 40|8@1- (0.78125,0) [-100|100] "%"  PDM1
 SG_ PDM004_CMD_DO06_PWM m4 : 48|8@1- (0.78125,0) [-100|100] "%"  PDM1
 SG_ PDM004_CMD_DO01_EN m4 : 56|1@1+ (1,0) [0|1] ""  PDM1
 SG_ PDM004_CMD_DO02_EN m4 : 57|1@1+ (1,0) [0|1] ""  PDM1
 SG_ PDM004_CMD_DO03_EN m4 : 58|1@1+ (1,0) [0|1] ""  PDM1
 SG_ PDM004_CMD_DO04_EN m4 : 59|1@1+ (1,0) [0|1] ""  PDM1
 SG_ PDM004_CMD_DO05_EN m4 : 60|1@1+ (1,0) [0|1] ""  PDM1
 SG_ PDM004_CMD_DO06_EN m4 : 61|1@1+ (1,0) [0|1] ""  PDM1
 SG_ PDM004_CMD_tx_rate m4 : 62|2@1+ (1,0) [0|1] ""  PDM1
 SG_ PDM005_CMD_DO07_PWM m5 : 8|8@1- (0.78125,0) [-100|100] "%"  PDM1
 SG_ PDM005_CMD_DO08_PWM m5 : 16|8@1- (0.78125,0) [-100|100] "%"  PDM1
 SG_ PDM005_CMD_DO09_PWM m5 : 24|8@1- (0.78125,0) [-100|100] "%"  PDM1
 SG_ PDM005_CMD_DO10_PWM m5 : 32|8@1- (0.78125,0) [-100|100] "%"  PDM1
 SG_ PDM005_CMD_DO11_PWM m5 : 40|8@1- (0.78125,0) [-100|100] "%"  PDM1
 SG_ PDM005_CMD_DO12_PWM m5 : 48|8@1- (0.78125,0) [-100|100] "%"  PDM1
 SG_ PDM005_CMD_DO07_EN m5 : 56|1@1+ (1,0) [0|1] ""  PDM1
 SG_ PDM005_CMD_DO08_EN m5 : 57|1@1+ (1,0) [0|1] ""  PDM1
 SG_ PDM005_CMD_DO09_EN m5 : 58|1@1+ (1,0) [0|1] ""  PDM1
 SG_ PDM005_CMD_DO10_EN m5 : 59|1@1+ (1,0) [0|1] ""  PDM1
 SG_ PDM005_CMD_DO11_EN m5 : 60|1@1+ (1,0) [0|1] ""  PDM1
 SG_ PDM005_CMD_DO12_EN m5 : 61|1@1+ (1,0) [0|1] ""  PDM1
 SG_ PDM006_CL_A_DO01 m6 : 8|4@1+ (2.5,0) [0|37] "A"  PDM1
 SG_ PDM006_Fb_type_DO01 m6 : 12|2@1+ (1,0) [0|3] ""  PDM1
SG_ PDM006_CL_A_DO01 m6 : 12|4@1+ (2.5,0) [0|37] "A"  PDM1
 SG_ PDM006_Fb_type_DO01 m6 : 10|2@1+ (1,0) [0|3] ""  PDM1
 SG_ PDM006_Auto_reset_DO01 m6 : 9|1@1+ (1,0) [0|1] ""  PDM1
 SG_ PDM006_HS_HB_DO01 m6 : 8|1@1+ (1,0) [0|1] ""  PDM1
 SG_ PDM006_CL_A_DO02 m6 : 20|4@1+ (2.5,0) [0|37] "A"  PDM1
 SG_ PDM006_Fb_type_DO02 m6 : 18|2@1+ (1,0) [0|3] ""  PDM1
 SG_ PDM006_Auto_reset_DO02 m6 : 17|1@1+ (1,0) [0|1] ""  PDM1
 SG_ PDM006_HS_HB_DO02 m6 : 16|1@1+ (1,0) [0|1] ""  PDM1
 SG_ PDM006_CL_A_DO03 m6 : 28|4@1+ (2.5,0) [0|37] "A"  PDM1
 SG_ PDM006_Fb_type_DO03 m6 : 26|2@1+ (1,0) [0|3] ""  PDM1
 SG_ PDM006_Auto_reset_DO03 m6 : 25|1@1+ (1,0) [0|1] ""  PDM1
 SG_ PDM006_HS_HB_DO03 m6 : 24|1@1+ (1,0) [0|1] ""  PDM1
 SG_ PDM006_CL_A_DO04 m6 : 36|4@1+ (2.5,0) [0|37] "A"  PDM1
 SG_ PDM006_Fb_type_DO04 m6 : 34|2@1+ (1,0) [0|3] ""  PDM1
 SG_ PDM006_Auto_reset_DO04 m6 : 33|1@1+ (1,0) [0|1] ""  PDM1
 SG_ PDM006_HS_HB_DO04 m6 : 32|1@1+ (1,0) [0|1] ""  PDM1
 SG_ PDM006_CL_A_DO05 m6 : 44|4@1+ (2.5,0) [0|37] "A"  PDM1
 SG_ PDM006_Fb_type_DO05 m6 : 42|2@1+ (1,0) [0|3] ""  PDM1
 SG_ PDM006_Auto_reset_DO05 m6 : 41|1@1+ (1,0) [0|1] ""  PDM1
 SG_ PDM006_HS_HB_DO05 m6 : 40|1@1+ (1,0) [0|1] ""  PDM1
 SG_ PDM006_CL_A_DO06 m6 : 52|4@1+ (2.5,0) [0|37] "A"  PDM1
 SG_ PDM006_Fb_type_DO06 m6 : 50|2@1+ (1,0) [0|3] ""  PDM1
 SG_ PDM006_Auto_reset_DO06 m6 : 49|1@1+ (1,0) [0|1] ""  PDM1
 SG_ PDM006_HS_HB_DO06 m6 : 48|1@1+ (1,0) [0|1] ""  PDM1
 SG_ PDM006_reserved_006 m6 : 56|8@1+ (1,0) [0|255] ""  PDM1
 SG_ PDM007_CL_A_DO07 m7 : 12|4@1+ (2.5,0) [0|37] "A"  PDM1
 SG_ PDM007_Fb_type_DO07 m7 : 10|2@1+ (1,0) [0|3] ""  PDM1
 SG_ PDM007_Auto_reset_DO07 m7 : 9|1@1+ (1,0) [0|1] ""  PDM1
 SG_ PDM007_HS_HB_DO07 m7 : 8|1@1+ (1,0) [0|1] ""  PDM1
 SG_ PDM007_CL_A_DO08 m7 : 20|4@1+ (2.5,0) [0|37] "A"  PDM1
 SG_ PDM007_Fb_type_DO08 m7 : 18|2@1+ (1,0) [0|3] ""  PDM1
 SG_ PDM007_Auto_reset_DO08 m7 : 17|1@1+ (1,0) [0|1] ""  PDM1
 SG_ PDM007_HS_HB_DO08 m7 : 16|1@1+ (1,0) [0|1] ""  PDM1
 SG_ PDM007_CL_A_DO09 m7 : 28|4@1+ (2.5,0) [0|37] "A"  PDM1
 SG_ PDM007_Fb_type_DO09 m7 : 26|2@1+ (1,0) [0|3] ""  PDM1
 SG_ PDM007_Auto_reset_DO09 m7 : 25|1@1+ (1,0) [0|1] ""  PDM1
 SG_ PDM007_HS_HB_DO09 m7 : 24|1@1+ (1,0) [0|1] ""  PDM1
 SG_ PDM007_CL_A_DO10 m7 : 36|4@1+ (2.5,0) [0|37] "A"  PDM1
 SG_ PDM007_Fb_type_DO10 m7 : 34|2@1+ (1,0) [0|3] ""  PDM1
 SG_ PDM007_Auto_reset_DO10 m7 : 33|1@1+ (1,0) [0|1] ""  PDM1
 SG_ PDM007_HS_HB_DO10 m7 : 32|1@1+ (1,0) [0|1] ""  PDM1
 SG_ PDM007_CL_A_DO11 m7 : 44|4@1+ (2.5,0) [0|37] "A"  PDM1
 SG_ PDM007_Fb_type_DO11 m7 : 42|2@1+ (1,0) [0|3] ""  PDM1
 SG_ PDM007_Auto_reset_DO11 m7 : 41|1@1+ (1,0) [0|1] ""  PDM1
 SG_ PDM007_HS_HB_DO11 m7 : 40|1@1+ (1,0) [0|1] ""  PDM1
 SG_ PDM007_CL_A_DO12 m7 : 52|4@1+ (2.5,0) [0|37] "A"  PDM1
 SG_ PDM007_Fb_type_DO12 m7 : 50|2@1+ (1,0) [0|3] ""  PDM1
 SG_ PDM007_Auto_reset_DO12 m7 : 49|1@1+ (1,0) [0|1] ""  PDM1
 SG_ PDM007_HS_HB_DO12 m7 : 48|1@1+ (1,0) [0|1] ""  PDM1
 SG_ PDM007_reserved_007 m7 : 56|8@1+ (1,0) [0|255] ""  PDM1

BO_ 2498695454 PDM_data: 8 PDM1
 SG_ PDM134_Output_Channel m134M : 8|8@1+ (1,0) [0|255] ""  CVC
 SG_ PDM_MULTIP_0 M : 0|8@1+ (1,0) [0|255] ""  CVC
 SG_ PDM128_DI01 m128 : 8|2@1+ (1,0) [0|3] ""  CVC
 SG_ PDM128_DI02 m128 : 10|2@1+ (1,0) [0|3] ""  CVC
 SG_ PDM128_DI03 m128 : 12|2@1+ (1,0) [0|3] ""  CVC
 SG_ PDM128_DI04 m128 : 14|2@1+ (1,0) [0|3] ""  CVC
 SG_ PDM128_DI05 m128 : 16|2@1+ (1,0) [0|3] ""  CVC
 SG_ PDM128_DI06 m128 : 18|2@1+ (1,0) [0|3] ""  CVC
 SG_ PDM128_DI07 m128 : 20|2@1+ (1,0) [0|3] ""  CVC
 SG_ PDM128_DI08 m128 : 22|2@1+ (1,0) [0|3] ""  CVC
 SG_ PDM128_DI09 m128 : 24|2@1+ (1,0) [0|3] ""  CVC
 SG_ PDM128_DI10 m128 : 26|2@1+ (1,0) [0|3] ""  CVC
 SG_ PDM128_DI11 m128 : 28|2@1+ (1,0) [0|3] ""  CVC
 SG_ PDM128_DI12 m128 : 30|2@1+ (1,0) [0|3] ""  CVC
 SG_ PDM128_AI1_Ohm m128 : 32|10@1+ (2.14844,0) [0|2197] "Ohm"  CVC
 SG_ PDM128_AI2_Ohm m128 : 48|10@1+ (2.14844,0) [0|2197] "Ohm"  CVC
 SG_ PDM129_Diag_DO01 m129 : 8|2@1+ (1,0) [0|3] ""  CVC
 SG_ PDM129_Diag_DO02 m129 : 10|2@1+ (1,0) [0|3] ""  CVC
 SG_ PDM129_Diag_DO03 m129 : 12|2@1+ (1,0) [0|3] ""  CVC
 SG_ PDM129_Diag_DO04 m129 : 14|2@1+ (1,0) [0|3] ""  CVC
 SG_ PDM129_Diag_DO05 m129 : 16|2@1+ (1,0) [0|3] ""  CVC
 SG_ PDM129_Diag_DO06 m129 : 18|2@1+ (1,0) [0|3] ""  CVC
 SG_ PDM129_Diag_DO07 m129 : 20|2@1+ (1,0) [0|3] ""  CVC
 SG_ PDM129_Diag_DO08 m129 : 22|2@1+ (1,0) [0|3] ""  CVC
 SG_ PDM129_Diag_DO09 m129 : 24|2@1+ (1,0) [0|3] ""  CVC
 SG_ PDM129_Diag_DO10 m129 : 26|2@1+ (1,0) [0|3] ""  CVC
 SG_ PDM129_Diag_DO11 m129 : 28|2@1+ (1,0) [0|3] ""  CVC
 SG_ PDM129_Diag_DO12 m129 : 30|2@1+ (1,0) [0|3] ""  CVC
 SG_ PDM129_AI3_V m129 : 32|10@1+ (0.00488281,0) [0|4] "V"  CVC
 SG_ PDM129_AI4_V m129 : 48|10@1+ (0.00488281,0) [0|4] "V"  CVC
 SG_ PDM130_reserved_130 m130 : 8|6@1+ (1,0) [0|63] ""  CVC
 SG_ PDM130_Sensor_supply_high m130 : 14|1@1+ (1,0) [0|1] ""  CVC
 SG_ PDM130_Sensor_supply_low m130 : 15|1@1+ (1,0) [0|1] ""  CVC
 SG_ PDM130_Battery_voltage m130 : 16|16@1+ (0.001,0) [0|64] "V"  CVC
 SG_ PDM130_AI5_V m130 : 32|10@1+ (0.00488281,0) [0|4] "V"  CVC
 SG_ PDM130_AI6_V m130 : 48|10@1+ (0.00488281,0) [0|4] "V"  CVC
 SG_ PDM131_Power_supply_status m131 : 14|1@1+ (1,0) [0|1] ""  CVC
 SG_ PDM131_Total_current_status m131 : 15|1@1+ (1,0) [0|1] "A"  CVC
 SG_ PDM131_Software_rev m131 : 16|16@1+ (1,0) [0|65535] ""  CVC
 SG_ PDM131_AI7_V m131 : 32|10@1+ (0.00488281,0) [0|4] "V"  CVC
 SG_ PDM131_AI8_V m131 : 48|10@1+ (0.00488281,0) [0|4] "V"  CVC
 SG_ PDM132_DO01_current_A m132 : 8|8@1+ (0.125,0) [0|31] "A"  CVC
 SG_ PDM132_DO02_current_A m132 : 16|8@1+ (0.125,0) [0|31] "A"  CVC
 SG_ PDM132_DO03_current_A m132 : 24|8@1+ (0.125,0) [0|31] "A"  CVC
 SG_ PDM132_DO04_current_A m132 : 32|8@1+ (0.125,0) [0|31] "A"  CVC
 SG_ PDM132_DO05_current_A m132 : 40|8@1+ (0.125,0) [0|31] "A"  CVC
 SG_ PDM132_DO06_current_A m132 : 48|8@1+ (0.125,0) [0|31] "A"  CVC
 SG_ PDM133_DO07_current_A m133 : 8|8@1+ (0.125,0) [0|31] "A"  CVC
 SG_ PDM133_DO08_current_A m133 : 16|8@1+ (0.125,0) [0|31] "A"  CVC
 SG_ PDM133_DO09_current_A m133 : 24|8@1+ (0.125,0) [0|31] "A"  CVC
 SG_ PDM133_DO10_current_A m133 : 32|8@1+ (0.125,0) [0|31] "A"  CVC
 SG_ PDM133_DO11_current_A m133 : 40|8@1+ (0.125,0) [0|31] "A"  CVC
 SG_ PDM133_DO12_current_A m133 : 48|8@1+ (0.125,0) [0|31] "A"  CVC
 SG_ PDM134_SS_Step_DO01 m1 : 16|8@1+ (1,0) [0|255] ""  CVC
 SG_ PDM134_M_L_DO01 m1 : 24|8@1+ (1,0) [0|255] ""  CVC
 SG_ PDM134_Loss_of_COMM_DO01 m1 : 32|8@1+ (1,0) [0|255] ""  CVC
 SG_ PDM134_POR_command_DO01 m1 : 48|5@1- (6.25,0) [0|93] ""  CVC
 SG_ PDM134_POR_En_DO01 m1 : 53|1@1+ (1,0) [0|1] ""  CVC
 SG_ PDM134_Command_type_DO01 m1 : 54|1@1+ (1,0) [0|1] ""  CVC
 SG_ PDM134_Motor_braking_DO01 m1 : 55|1@1+ (1,0) [0|1] ""  CVC
 SG_ PDM134_LSC_DO01 m1 : 56|4@1+ (1,0) [0|15] ""  CVC
 SG_ PDM134_Calib_time_DO01 m1 : 60|2@1+ (1,0) [0|3] ""  CVC
 SG_ PDM134_Response_DO01 m1 : 62|2@1+ (1,0) [0|3] ""  CVC
 SG_ PDM134_SS_Step_DO02 m2 : 16|8@1+ (1,0) [0|255] ""  CVC
 SG_ PDM134_M_L_DO02 m2 : 24|8@1+ (1,0) [0|255] ""  CVC
 SG_ PDM134_Loss_of_COMM_DO02 m2 : 32|8@1+ (1,0) [0|255] ""  CVC
 SG_ PDM134_POR_command_DO02 m2 : 48|5@1- (6.25,0) [0|93] ""  CVC
 SG_ PDM134_POR_En_DO02 m2 : 53|1@1+ (1,0) [0|1] ""  CVC
 SG_ PDM134_Command_type_DO02 m2 : 54|1@1+ (1,0) [0|1] ""  CVC
 SG_ PDM134_Motor_braking_DO02 m2 : 55|1@1+ (1,0) [0|1] ""  CVC
 SG_ PDM134_LSC_DO02 m2 : 56|4@1+ (1,0) [0|15] ""  CVC
 SG_ PDM134_Calib_time_DO02 m2 : 60|2@1+ (1,0) [0|3] ""  CVC
 SG_ PDM134_Response_DO02 m2 : 62|2@1+ (1,0) [0|3] ""  CVC
 SG_ PDM134_SS_Step_DO03 m3 : 16|8@1+ (1,0) [0|255] ""  CVC
 SG_ PDM134_M_L_DO03 m3 : 24|8@1+ (1,0) [0|255] ""  CVC
 SG_ PDM134_Loss_of_COMM_DO03 m3 : 32|8@1+ (1,0) [0|255] ""  CVC
 SG_ PDM134_POR_command_DO03 m3 : 48|5@1- (6.25,0) [0|93] ""  CVC
 SG_ PDM134_POR_En_DO03 m3 : 53|1@1+ (1,0) [0|1] ""  CVC
 SG_ PDM134_Command_type_DO03 m3 : 54|1@1+ (1,0) [0|1] ""  CVC
 SG_ PDM134_Motor_braking_DO03 m3 : 55|1@1+ (1,0) [0|1] ""  CVC
 SG_ PDM134_LSC_DO03 m3 : 56|4@1+ (1,0) [0|15] ""  CVC
 SG_ PDM134_Calib_time_DO03 m3 : 60|2@1+ (1,0) [0|3] ""  CVC
 SG_ PDM134_Response_DO03 m3 : 62|2@1+ (1,0) [0|3] ""  CVC
 SG_ PDM134_SS_Step_DO04 m4 : 16|8@1+ (1,0) [0|255] ""  CVC
 SG_ PDM134_M_L_DO04 m4 : 24|8@1+ (1,0) [0|255] ""  CVC
 SG_ PDM134_Loss_of_COMM_DO04 m4 : 32|8@1+ (1,0) [0|255] ""  CVC
 SG_ PDM134_POR_command_DO04 m4 : 48|5@1- (6.25,0) [0|93] ""  CVC
 SG_ PDM134_POR_En_DO04 m4 : 53|1@1+ (1,0) [0|1] ""  CVC
 SG_ PDM134_Command_type_DO04 m4 : 54|1@1+ (1,0) [0|1] ""  CVC
 SG_ PDM134_Motor_braking_DO04 m4 : 55|1@1+ (1,0) [0|1] ""  CVC
 SG_ PDM134_LSC_DO04 m4 : 56|4@1+ (1,0) [0|15] ""  CVC
 SG_ PDM134_Calib_time_DO04 m4 : 60|2@1+ (1,0) [0|3] ""  CVC
 SG_ PDM134_Response_DO04 m4 : 62|2@1+ (1,0) [0|3] ""  CVC
 SG_ PDM134_SS_Step_DO05 m5 : 16|8@1+ (1,0) [0|255] ""  CVC
 SG_ PDM134_M_L_DO05 m5 : 24|8@1+ (1,0) [0|255] ""  CVC
 SG_ PDM134_Loss_of_COMM_DO05 m5 : 32|8@1+ (1,0) [0|255] ""  CVC
 SG_ PDM134_POR_command_DO05 m5 : 48|5@1- (6.25,0) [0|93] ""  CVC
 SG_ PDM134_POR_En_DO05 m5 : 53|1@1+ (1,0) [0|1] ""  CVC
 SG_ PDM134_Command_type_DO05 m5 : 54|1@1+ (1,0) [0|1] ""  CVC
 SG_ PDM134_Motor_braking_DO05 m5 : 55|1@1+ (1,0) [0|1] ""  CVC
 SG_ PDM134_LSC_DO05 m5 : 56|4@1+ (1,0) [0|15] ""  CVC
 SG_ PDM134_Calib_time_DO05 m5 : 60|2@1+ (1,0) [0|3] ""  CVC
 SG_ PDM134_Response_DO05 m5 : 62|2@1+ (1,0) [0|3] ""  CVC
 SG_ PDM134_SS_Step_DO06 m6 : 16|8@1+ (1,0) [0|255] ""  CVC
 SG_ PDM134_M_L_DO06 m6 : 24|8@1+ (1,0) [0|255] ""  CVC
 SG_ PDM134_Loss_of_COMM_DO06 m6 : 32|8@1+ (1,0) [0|255] ""  CVC
 SG_ PDM134_POR_command_DO06 m6 : 48|5@1- (6.25,0) [0|93] ""  CVC
 SG_ PDM134_POR_En_DO06 m6 : 53|1@1+ (1,0) [0|1] ""  CVC
 SG_ PDM134_Command_type_DO06 m6 : 54|1@1+ (1,0) [0|1] ""  CVC
 SG_ PDM134_Motor_braking_DO06 m6 : 55|1@1+ (1,0) [0|1] ""  CVC
 SG_ PDM134_LSC_DO06 m6 : 56|4@1+ (1,0) [0|15] ""  CVC
 SG_ PDM134_Calib_time_DO06 m6 : 60|2@1+ (1,0) [0|3] ""  CVC
 SG_ PDM134_Response_DO06 m6 : 62|2@1+ (1,0) [0|3] ""  CVC
 SG_ PDM134_SS_Step_DO07 m7 : 16|8@1+ (1,0) [0|255] ""  CVC
 SG_ PDM134_M_L_DO07 m7 : 24|8@1+ (1,0) [0|255] ""  CVC
 SG_ PDM134_Loss_of_COMM_DO07 m7 : 32|8@1+ (1,0) [0|255] ""  CVC
 SG_ PDM134_POR_command_DO07 m7 : 48|5@1- (6.25,0) [0|93] ""  CVC
 SG_ PDM134_POR_En_DO07 m7 : 53|1@1+ (1,0) [0|1] ""  CVC
 SG_ PDM134_Command_type_DO07 m7 : 54|1@1+ (1,0) [0|1] ""  CVC
 SG_ PDM134_Motor_braking_DO07 m7 : 55|1@1+ (1,0) [0|1] ""  CVC
 SG_ PDM134_LSC_DO07 m7 : 56|4@1+ (1,0) [0|15] ""  CVC
 SG_ PDM134_Calib_time_DO07 m7 : 60|2@1+ (1,0) [0|3] ""  CVC
 SG_ PDM134_Response_DO07 m7 : 62|2@1+ (1,0) [0|3] ""  CVC
 SG_ PDM134_SS_Step_DO08 m8 : 16|8@1+ (1,0) [0|255] ""  CVC
 SG_ PDM134_M_L_DO08 m8 : 24|8@1+ (1,0) [0|255] ""  CVC
 SG_ PDM134_Loss_of_COMM_DO08 m8 : 32|8@1+ (1,0) [0|255] ""  CVC
 SG_ PDM134_POR_command_DO08 m8 : 48|5@1- (6.25,0) [0|93] ""  CVC
 SG_ PDM134_POR_En_DO08 m8 : 53|1@1+ (1,0) [0|1] ""  CVC
 SG_ PDM134_Command_type_DO08 m8 : 54|1@1+ (1,0) [0|1] ""  CVC
 SG_ PDM134_Motor_braking_DO08 m8 : 55|1@1+ (1,0) [0|1] ""  CVC
 SG_ PDM134_LSC_DO08 m8 : 56|4@1+ (1,0) [0|15] ""  CVC
 SG_ PDM134_Calib_time_DO08 m8 : 60|2@1+ (1,0) [0|3] ""  CVC
 SG_ PDM134_Response_DO08 m8 : 62|2@1+ (1,0) [0|3] ""  CVC
 SG_ PDM134_SS_Step_DO09 m9 : 16|8@1+ (1,0) [0|255] ""  CVC
 SG_ PDM134_M_L_DO09 m9 : 24|8@1+ (1,0) [0|255] ""  CVC
 SG_ PDM134_Loss_of_COMM_DO09 m9 : 32|8@1+ (1,0) [0|255] ""  CVC
 SG_ PDM134_POR_command_DO09 m9 : 48|5@1- (6.25,0) [0|93] ""  CVC
 SG_ PDM134_POR_En_DO09 m9 : 53|1@1+ (1,0) [0|1] ""  CVC
 SG_ PDM134_Command_type_DO09 m9 : 54|1@1+ (1,0) [0|1] ""  CVC
 SG_ PDM134_Motor_braking_DO09 m9 : 55|1@1+ (1,0) [0|1] ""  CVC
 SG_ PDM134_LSC_DO09 m9 : 56|4@1+ (1,0) [0|15] ""  CVC
 SG_ PDM134_Calib_time_DO09 m9 : 60|2@1+ (1,0) [0|3] ""  CVC
 SG_ PDM134_Response_DO09 m9 : 62|2@1+ (1,0) [0|3] ""  CVC
 SG_ PDM134_SS_Step_DO10 m10 : 16|8@1+ (1,0) [0|255] ""  CVC
 SG_ PDM134_M_L_DO10 m10 : 24|8@1+ (1,0) [0|255] ""  CVC
 SG_ PDM134_Loss_of_COMM_DO10 m10 : 32|8@1+ (1,0) [0|255] ""  CVC
 SG_ PDM134_POR_command_DO10 m10 : 48|5@1- (6.25,0) [0|93] ""  CVC
 SG_ PDM134_POR_En_DO10 m10 : 53|1@1+ (1,0) [0|1] ""  CVC
 SG_ PDM134_Command_type_DO10 m10 : 54|1@1+ (1,0) [0|1] ""  CVC
 SG_ PDM134_Motor_braking_DO10 m10 : 55|1@1+ (1,0) [0|1] ""  CVC
 SG_ PDM134_LSC_DO10 m10 : 56|4@1+ (1,0) [0|15] ""  CVC
 SG_ PDM134_Calib_time_DO10 m10 : 60|2@1+ (1,0) [0|3] ""  CVC
 SG_ PDM134_Response_DO10 m10 : 62|2@1+ (1,0) [0|3] ""  CVC
 SG_ PDM134_SS_Step_DO11 m11 : 16|8@1+ (1,0) [0|255] ""  CVC
 SG_ PDM134_M_L_DO11 m11 : 24|8@1+ (1,0) [0|255] ""  CVC
 SG_ PDM134_Loss_of_COMM_DO11 m11 : 32|8@1+ (1,0) [0|255] ""  CVC
 SG_ PDM134_POR_command_DO11 m11 : 48|5@1- (6.25,0) [0|93] ""  CVC
 SG_ PDM134_POR_En_DO11 m11 : 53|1@1+ (1,0) [0|1] ""  CVC
 SG_ PDM134_Command_type_DO11 m11 : 54|1@1+ (1,0) [0|1] ""  CVC
 SG_ PDM134_Motor_braking_DO11 m11 : 55|1@1+ (1,0) [0|1] ""  CVC
 SG_ PDM134_LSC_DO11 m11 : 56|4@1+ (1,0) [0|15] ""  CVC
 SG_ PDM134_Calib_time_DO11 m11 : 60|2@1+ (1,0) [0|3] ""  CVC
 SG_ PDM134_Response_DO11 m11 : 62|2@1+ (1,0) [0|3] ""  CVC
 SG_ PDM134_SS_Step_DO12 m12 : 16|8@1+ (1,0) [0|255] ""  CVC
 SG_ PDM134_M_L_DO12 m12 : 24|8@1+ (1,0) [0|255] ""  CVC
 SG_ PDM134_Loss_of_COMM_DO12 m12 : 32|8@1+ (1,0) [0|255] ""  CVC
 SG_ PDM134_POR_command_DO12 m12 : 48|5@1- (6.25,0) [0|93] ""  CVC
 SG_ PDM134_POR_En_DO12 m12 : 53|1@1+ (1,0) [0|1] ""  CVC
 SG_ PDM134_Command_type_DO12 m12 : 54|1@1+ (1,0) [0|1] ""  CVC
 SG_ PDM134_Motor_braking_DO12 m12 : 55|1@1+ (1,0) [0|1] ""  CVC
 SG_ PDM134_LSC_DO12 m12 : 56|4@1+ (1,0) [0|15] ""  CVC
 SG_ PDM134_Calib_time_DO12 m12 : 60|2@1+ (1,0) [0|3] ""  CVC
 SG_ PDM134_Response_DO12 m12 : 62|2@1+ (1,0) [0|3] ""  CVC
 SG_ PDM135_CL_A_DO01 m135 : 12|4@1+ (2.5,0) [0|37] "A"  CVC
 SG_ PDM135_Fb_type_DO01 m135 : 10|2@1+ (1,0) [0|3] ""  CVC
 SG_ PDM135_Auto_reset_DO01 m135 : 9|1@1+ (1,0) [0|1] ""  CVC
 SG_ PDM135_HS_HB_DO01 m135 : 8|1@1+ (1,0) [0|1] ""  CVC
 SG_ PDM135_CL_A_DO02 m135 : 20|4@1+ (2.5,0) [0|37] "A"  CVC
 SG_ PDM135_Fb_type_DO02 m135 : 18|2@1+ (1,0) [0|3] ""  CVC
 SG_ PDM135_Auto_reset_DO02 m135 : 17|1@1+ (1,0) [0|1] ""  CVC
 SG_ PDM135_HS_HB_DO02 m135 : 16|1@1+ (1,0) [0|1] ""  CVC
 SG_ PDM135_CL_A_DO03 m135 : 28|4@1+ (2.5,0) [0|37] "A"  CVC
 SG_ PDM135_Fb_type_DO03 m135 : 26|2@1+ (1,0) [0|3] ""  CVC
 SG_ PDM135_Auto_reset_DO03 m135 : 25|1@1+ (1,0) [0|1] ""  CVC
 SG_ PDM135_HS_HB_DO03 m135 : 24|1@1+ (1,0) [0|1] ""  CVC
 SG_ PDM135_CL_A_DO04 m135 : 36|4@1+ (2.5,0) [0|37] "A"  CVC
 SG_ PDM135_Fb_type_DO04 m135 : 34|2@1+ (1,0) [0|3] ""  CVC
 SG_ PDM135_Auto_reset_DO04 m135 : 33|1@1+ (1,0) [0|1] ""  CVC
 SG_ PDM135_HS_HB_DO04 m135 : 32|1@1+ (1,0) [0|1] ""  CVC
 SG_ PDM135_CL_A_DO05 m135 : 44|4@1+ (2.5,0) [0|37] "A"  CVC
 SG_ PDM135_Fb_type_DO05 m135 : 42|2@1+ (1,0) [0|3] ""  CVC
 SG_ PDM135_Auto_reset_DO05 m135 : 41|1@1+ (1,0) [0|1] ""  CVC
 SG_ PDM135_HS_HB_DO05 m135 : 40|1@1+ (1,0) [0|1] ""  CVC
 SG_ PDM135_CL_A_DO06 m135 : 52|4@1+ (2.5,0) [0|37] "A"  CVC
 SG_ PDM135_Fb_type_DO06 m135 : 50|2@1+ (1,0) [0|3] ""  CVC
 SG_ PDM135_Auto_reset_DO06 m135 : 49|1@1+ (1,0) [0|1] ""  CVC
 SG_ PDM135_HS_HB_DO06 m135 : 48|1@1+ (1,0) [0|1] ""  CVC
 SG_ PDM135_reserved_135 m135 : 56|8@1+ (1,0) [0|255] ""  CVC
 SG_ PDM136_CL_A_DO07 m136 : 12|4@1+ (2.5,0) [0|37] "A"  CVC
 SG_ PDM136_Fb_type_DO07 m136 : 10|2@1+ (1,0) [0|3] ""  CVC
 SG_ PDM136_Auto_reset_DO07 m136 : 9|1@1+ (1,0) [0|1] ""  CVC
 SG_ PDM136_HS_HB_DO07 m136 : 8|1@1+ (1,0) [0|1] ""  CVC
 SG_ PDM136_CL_A_DO08 m136 : 20|4@1+ (2.5,0) [0|37] "A"  CVC
 SG_ PDM136_Fb_type_DO08 m136 : 18|2@1+ (1,0) [0|3] ""  CVC
 SG_ PDM136_Auto_reset_DO08 m136 : 17|1@1+ (1,0) [0|1] ""  CVC
 SG_ PDM136_HS_HB_DO08 m136 : 16|1@1+ (1,0) [0|1] ""  CVC
 SG_ PDM136_CL_A_DO09 m136 : 28|4@1+ (2.5,0) [0|37] "A"  CVC
 SG_ PDM136_Fb_type_DO09 m136 : 26|2@1+ (1,0) [0|3] ""  CVC
 SG_ PDM136_Auto_reset_DO09 m136 : 25|1@1+ (1,0) [0|1] ""  CVC
 SG_ PDM136_HS_HB_DO09 m136 : 24|1@1+ (1,0) [0|1] ""  CVC
 SG_ PDM136_CL_A_DO10 m136 : 36|4@1+ (2.5,0) [0|37] "A"  CVC
 SG_ PDM136_Fb_type_DO10 m136 : 34|2@1+ (1,0) [0|3] ""  CVC
 SG_ PDM136_Auto_reset_DO10 m136 : 33|1@1+ (1,0) [0|1] ""  CVC
 SG_ PDM136_HS_HB_DO10 m136 : 32|1@1+ (1,0) [0|1] ""  CVC
 SG_ PDM136_CL_A_DO11 m136 : 44|4@1+ (2.5,0) [0|37] "A"  CVC
 SG_ PDM136_Fb_type_DO11 m136 : 42|2@1+ (1,0) [0|3] ""  CVC
 SG_ PDM136_Auto_reset_DO11 m136 : 41|1@1+ (1,0) [0|1] ""  CVC
 SG_ PDM136_HS_HB_DO11 m136 : 40|1@1+ (1,0) [0|1] ""  CVC
 SG_ PDM136_CL_A_DO12 m136 : 52|4@1+ (2.5,0) [0|37] "A"  CVC
 SG_ PDM136_Fb_type_DO12 m136 : 50|2@1+ (1,0) [0|3] ""  CVC
 SG_ PDM136_Auto_reset_DO12 m136 : 49|1@1+ (1,0) [0|1] ""  CVC
 SG_ PDM136_HS_HB_DO12 m136 : 48|1@1+ (1,0) [0|1] ""  CVC
 SG_ PDM136_reserved_136 m136 : 56|8@1+ (1,0) [0|255] ""  CVC

BO_ 2566869221 DCDC1_1: 8 DCDC1
 SG_ DCDC_Out_V : 7|16@0+ (0.1,0) [0|6553] ""  CVC
 SG_ DCDC_Out_I : 23|16@0+ (0.1,0) [0|6553] ""  CVC
 SG_ DCDC_ON : 34|1@0+ (1,0) [0|1] ""  CVC
 SG_ DCDC_input_failure : 35|1@0+ (1,0) [0|1] ""  CVC
 SG_ DCDC_Out_overcurrent : 36|1@0+ (1,0) [0|1] "A"  CVC
 SG_ DCDC_Secondary_OTP : 37|1@0+ (1,0) [0|1] ""  CVC
 SG_ DCDC_Out_Undervoltage : 38|1@0+ (1,0) [0|1] "V"  CVC
 SG_ DCDC_Out_Overvoltage : 39|1@0+ (1,0) [0|1] "V"  CVC
 SG_ DCDC_Input_V : 47|16@0+ (0.1,0) [0|6553.5] "V"  CVC
 SG_ DCDC_Primary_OTP : 59|1@0+ (1,0) [0|1] ""  CVC
 SG_ DCDC_Input_Voltage_Failure : 60|1@0+ (1,0) [0|1] "V"  CVC
 SG_ DCDC_Input_Range : 61|1@0+ (1,0) [0|1] ""  CVC
 SG_ DCDC_Input_Under_Voltage : 62|1@0+ (1,0) [0|1] "V"  CVC
 SG_ DCDC_Input_Over_voltage : 63|1@0+ (1,0) [0|1] "V"  CVC

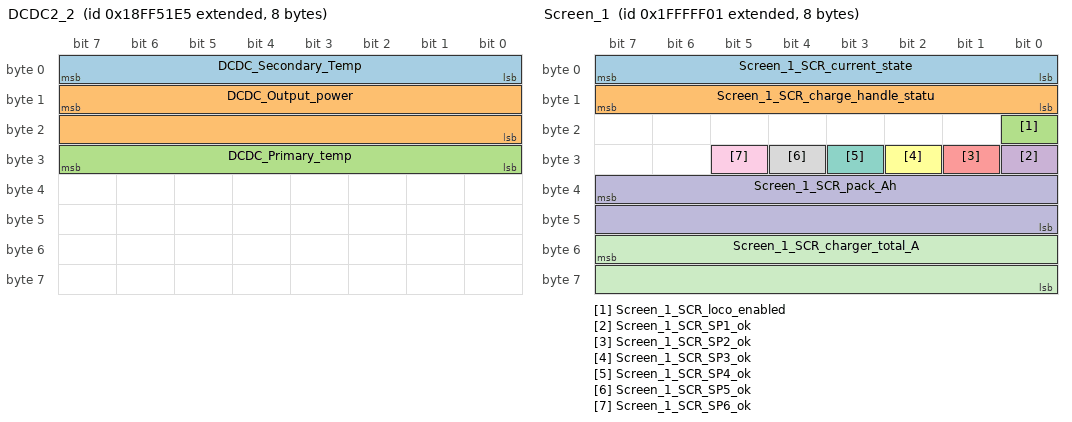
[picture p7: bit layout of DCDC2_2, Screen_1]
BO_ 2566869477 DCDC2_2: 8 DCDC1
 SG_ DCDC_Secondary_Temp : 7|8@0+ (1,0) [0|255] "C"  CVC
 SG_ DCDC_Output_power : 15|16@0+ (1,0) [0|60000] "W"  CVC
 SG_ DCDC_Primary_temp : 31|8@0+ (1,0) [0|255] "C"  CVC

BO_ 2684354305 Screen_1: 8 CVC
 SG_ Screen_1_SCR_current_state : 0|8@1+ (1,0) [0|255] "A"  Screen
 SG_ Screen_1_SCR_charge_handle_statu : 8|8@1+ (1,0) [0|255] ""  Screen
 SG_ Screen_1_SCR_loco_enabled : 16|1@1+ (1,0) [0|1] ""  Screen
 SG_ Screen_1_SCR_SP1_ok : 24|1@1+ (1,0) [0|1] ""  Screen
 SG_ Screen_1_SCR_SP2_ok : 25|1@1+ (1,0) [0|1] ""  Screen
 SG_ Screen_1_SCR_SP3_ok : 26|1@1+ (1,0) [0|1] ""  Screen
 SG_ Screen_1_SCR_SP4_ok : 27|1@1+ (1,0) [0|1] ""  Screen
 SG_ Screen_1_SCR_SP5_ok : 28|1@1+ (1,0) [0|1] ""  Screen
 SG_ Screen_1_SCR_SP6_ok : 29|1@1+ (1,0) [0|1] ""  Screen
 SG_ Screen_1_SCR_pack_Ah : 39|16@0+ (0.1,0) [0|6553] "Ah"  Screen
 SG_ Screen_1_SCR_charger_total_A : 55|16@0+ (0.1,0) [0|6553] "A"  Screen

BO_ 2684354306 Screen_2: 8 CVC
 SG_ Screen_2_SCR_loco_distance_km : 0|32@1+ (0.000277778,0) [0|1193050] "km"  Screen
 SG_ Screen_2_SCR_loco_runtime_hrs : 32|32@1+ (0.000277778,0) [0|1193050] "hrs"  Screen

BO_ 2684354307 Screen_3: 8 CVC
 SG_ Screen_3_Firmware_version : 0|16@1+ (0.1,0) [0|6553] ""  Screen
 SG_ Screen_3_Battery_SN : 16|8@1+ (1,0) [0|255] ""  Screen
 SG_ Screen_3_precharge_relay_SP1 : 24|1@1+ (1,0) [0|1] ""  Screen
 SG_ Screen_3_precharge_relay_SP2 : 25|1@1+ (1,0) [0|1] ""  Screen
 SG_ Screen_3_precharge_relay_SP3 : 26|1@1+ (1,0) [0|1] ""  Screen
 SG_ Screen_3_precharge_relay_SP4 : 27|1@1+ (1,0) [0|1] ""  Screen
 SG_ Screen_3_precharge_relay_SP5 : 28|1@1+ (1,0) [0|1] ""  Screen
 SG_ Screen_3_precharge_relay_SP6 : 29|1@1+ (1,0) [0|1] ""  Screen
 SG_ Screen_3_pos_fb_SP1 : 32|1@1+ (1,0) [0|1] ""  Screen
 SG_ Screen_3_pos_fb_SP2 : 33|1@1+ (1,0) [0|1] ""  Screen
 SG_ Screen_3_pos_fb_SP3 : 34|1@1+ (1,0) [0|1] ""  Screen
 SG_ Screen_3_pos_fb_SP4 : 35|1@1+ (1,0) [0|1] ""  Screen
 SG_ Screen_3_pos_fb_SP5 : 36|1@1+ (1,0) [0|1] ""  Screen
 SG_ Screen_3_pos_fb_SP6 : 37|1@1+ (1,0) [0|1] ""  Screen
 SG_ Screen_3_neg_fb_SP1 : 40|1@1+ (1,0) [0|1] ""  Screen
 SG_ Screen_3_neg_fb_SP2 : 41|1@1+ (1,0) [0|1] ""  Screen
 SG_ Screen_3_neg_fb_SP3 : 42|1@1+ (1,0) [0|1] ""  Screen
 SG_ Screen_3_neg_fb_SP4 : 43|1@1+ (1,0) [0|1] ""  Screen
 SG_ Screen_3_neg_fb_SP5 : 44|1@1+ (1,0) [0|1] ""  Screen
 SG_ Screen_3_neg_fb_SP6 : 45|1@1+ (1,0) [0|1] ""  Screen
 SG_ Screen_3_SCR_pump_on_status : 48|1@1+ (1,0) [0|1] ""  Screen
 SG_ Screen_3_SCR_fan_on_status : 49|1@1+ (1,0) [0|1] ""  Screen

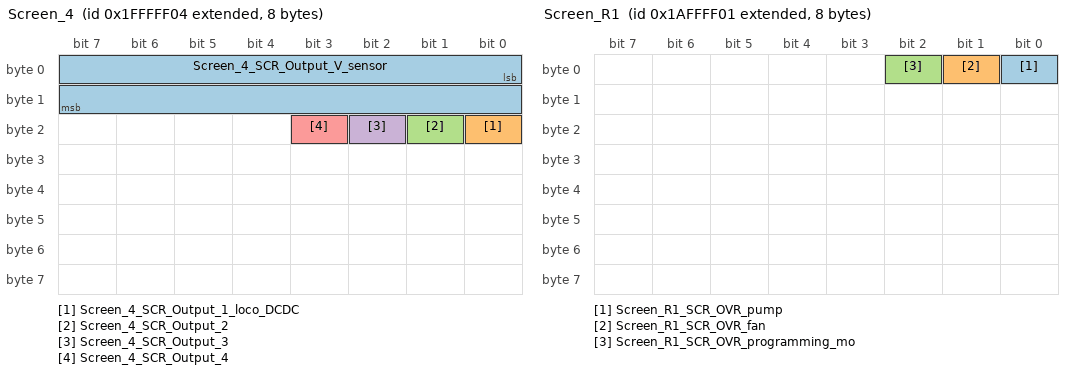
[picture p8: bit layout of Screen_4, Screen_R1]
BO_ 2684354308 Screen_4: 8 CVC
 SG_ Screen_4_SCR_Output_V_sensor : 0|16@1+ (0.01,0) [0|655] ""  Screen
 SG_ Screen_4_SCR_Output_1_loco_DCDC : 16|1@1+ (1,0) [0|1] "loco DCDC"  Screen
 SG_ Screen_4_SCR_Output_2 : 17|1@1+ (1,0) [0|1] ""  Screen
 SG_ Screen_4_SCR_Output_3 : 18|1@1+ (1,0) [0|1] ""  Screen
 SG_ Screen_4_SCR_Output_4 : 19|1@1+ (1,0) [0|1] ""  Screen

BO_ 2600468225 Screen_R1: 8 Screen
 SG_ Screen_R1_SCR_OVR_pump : 0|1@1+ (1,0) [0|1] ""  CVC
 SG_ Screen_R1_SCR_OVR_fan : 1|1@1+ (1,0) [0|1] ""  CVC
 SG_ Screen_R1_SCR_OVR_programming_mo : 2|1@1+ (1,0) [0|1] ""  CVC

CM_ BU_ LOCO_PLC "Comms with the locomotive";
CM_ BU_ Screen "The 7in Service Screen";
CM_ BU_ DCDC1 "HV to 24VDC";
CM_ BU_ CVC "The Central Vehicle Controller";
CM_ BU_ Telematics "The CanEdge2 telematics unit";
CM_ BU_ PDM1 "A Power Distribution Module";
BA_DEF_  "DBName" STRING ;
BA_DEF_  "BusType" STRING ;
BA_DEF_ BU_  "NmStationAddress" INT 0 255;
BA_DEF_ BU_  "DeviceInfo" STRING ;
BA_DEF_ BO_  "CanDootDecode" ENUM  "No","Yes";
BA_DEF_ BO_  "CanDootPaused" ENUM  "No","Yes";
BA_DEF_ BO_  "CanDootSimulate" ENUM  "No","Yes";
BA_DEF_ BO_  "CanDootSimulateCycleTime" INT 0 50000;
BA_DEF_ SG_  "CanDootHidden" ENUM  "No","Yes";
BA_DEF_ BO_  "CANFD_BRS" ENUM  "0","1";
BA_DEF_ BO_  "VFrameFormat" ENUM  "StandardCAN","ExtendedCAN","reserved","J1939PG","reserved","reserved","reserved","reserved","reserved","reserved","reserved","reserved","reserved","reserved","StandardCAN_FD","ExtendedCAN_FD";
BA_DEF_DEF_  "DBName" "";
BA_DEF_DEF_  "BusType" "CAN";
BA_DEF_DEF_  "NmStationAddress" 254;
BA_DEF_DEF_  "DeviceInfo" "";
BA_DEF_DEF_  "CanDootDecode" "No";
BA_DEF_DEF_  "CanDootPaused" "Yes";
BA_DEF_DEF_  "CanDootSimulate" "No";
BA_DEF_DEF_  "CanDootSimulateCycleTime" 1500;
BA_DEF_DEF_  "CanDootHidden" "No";
BA_DEF_DEF_  "CANFD_BRS" "1";
BA_DEF_DEF_  "VFrameFormat" "ExtendedCAN";
BA_ "BusType" "CAN FD";
BA_ "DBName" "loco_CAN250";
BA_ "NmStationAddress" BU_ LOCO_PLC 244;
BA_ "NmStationAddress" BU_ Screen 249;
BA_ "DeviceInfo" BU_ Screen "HED CL711_111";
BA_ "NmStationAddress" BU_ DCDC1 243;
BA_ "DeviceInfo" BU_ DCDC1 "EGTRONICS ACU28V10K";
BA_ "NmStationAddress" BU_ CVC 17;
BA_ "DeviceInfo" BU_ CVC "HED CL450-101-10";
BA_ "NmStationAddress" BU_ Telematics 252;
BA_ "DeviceInfo" BU_ Telematics "HED CL711_111";
BA_ "NmStationAddress" BU_ PDM1 30;
BA_ "DeviceInfo" BU_ PDM1 "Murphy IX3212";
BA_ "CanDootDecode" BO_ 2147545100 1;
BA_ "CanDootPaused" BO_ 2147545100 0;
BA_ "CanDootDecode" BO_ 2147545099 1;
BA_ "CanDootPaused" BO_ 2147545099 0;
BA_ "CanDootDecode" BO_ 2147545097 1;
BA_ "CanDootPaused" BO_ 2147545097 0;
BA_ "CanDootDecode" BO_ 2147545096 1;
BA_ "CanDootPaused" BO_ 2147545096 0;
BA_ "CanDootDecode" BO_ 2147484176 1;
BA_ "CanDootPaused" BO_ 2147484176 0;
BA_ "CanDootDecode" BO_ 2147484177 1;
BA_ "CanDootPaused" BO_ 2147484177 0;
BA_ "CanDootDecode" BO_ 2147484178 1;
BA_ "CanDootPaused" BO_ 2147484178 0;
BA_ "CanDootDecode" BO_ 2498698769 1;
BA_ "CanDootDecode" BO_ 2498695454 1;
BA_ "CanDootPaused" BO_ 2498695454 0;
BA_ "CanDootDecode" BO_ 2684354305 1;
BA_ "CanDootPaused" BO_ 2684354305 0;
BA_ "CanDootDecode" BO_ 2684354306 1;
BA_ "CanDootPaused" BO_ 2684354306 0;
BA_ "CanDootDecode" BO_ 2684354307 1;
BA_ "CanDootPaused" BO_ 2684354307 0;
BA_ "CanDootDecode" BO_ 2684354308 1;
BA_ "CanDootPaused" BO_ 2684354308 0;
BA_ "CanDootPaused" BO_ 2600468225 0;
BA_ "CanDootSimulate" BO_ 2600468225 1;
SIG_GROUP_ 2498698769 PDM000_Out_hs_12 1 : PDM000_SS_Step_DO12 PDM000_M_L_DO12 PDM000_Loss_of_COMM_DO12 PDM000_POR_command_DO12 PDM000_POR_En_DO12 PDM000_Command_type_DO12 PDM000_Motor_braking_DO12 PDM000_LSC_DO12 PDM000_Calib_time_DO12 PDM000_Response_DO12;
SIG_GROUP_ 2498698769 PDM000_Out_hs_11 1 : PDM000_SS_Step_DO11 PDM000_M_L_DO11 PDM000_Loss_of_COMM_DO11 PDM000_POR_command_DO11 PDM000_POR_En_DO11 PDM000_Command_type_DO11 PDM000_Motor_braking_DO11 PDM000_LSC_DO11 PDM000_Calib_time_DO11 PDM000_Response_DO11;
SIG_GROUP_ 2498698769 PDM000_Out_hs_10 1 : PDM000_SS_Step_DO10 PDM000_M_L_DO10 PDM000_Loss_of_COMM_DO10 PDM000_POR_command_DO10 PDM000_POR_En_DO10 PDM000_Command_type_DO10 PDM000_Motor_braking_DO10 PDM000_LSC_DO10 PDM000_Calib_time_DO10 PDM000_Response_DO10;
SIG_GROUP_ 2498698769 PDM000_Out_hs_09 1 : PDM000_SS_Step_DO09 PDM000_M_L_DO09 PDM000_Loss_of_COMM_DO09 PDM000_POR_command_DO09 PDM000_POR_En_DO09 PDM000_Command_type_DO09 PDM000_Motor_braking_DO09 PDM000_LSC_DO09 PDM000_Calib_time_DO09 PDM000_Response_DO09;
SIG_GROUP_ 2498698769 PDM000_Out_hs_08 1 : PDM000_SS_Step_DO08 PDM000_M_L_DO08 PDM000_Loss_of_COMM_DO08 PDM000_POR_command_DO08 PDM000_POR_En_DO08 PDM000_Command_type_DO08 PDM000_Motor_braking_DO08 PDM000_LSC_DO08 PDM000_Calib_time_DO08 PDM000_Response_DO08;
SIG_GROUP_ 2498698769 PDM000_Out_hs_07 1 : PDM000_SS_Step_DO07 PDM000_M_L_DO07 PDM000_Loss_of_COMM_DO07 PDM000_POR_command_DO07 PDM000_POR_En_DO07 PDM000_Command_type_DO07 PDM000_Motor_braking_DO07 PDM000_LSC_DO07 PDM000_Calib_time_DO07 PDM000_Response_DO07;
SIG_GROUP_ 2498698769 PDM000_Out_hs_06 1 : PDM000_SS_Step_DO06 PDM000_M_L_DO06 PDM000_Loss_of_COMM_DO06 PDM000_POR_command_DO06 PDM000_POR_En_DO06 PDM000_Command_type_DO06 PDM000_Motor_braking_DO06 PDM000_LSC_DO06 PDM000_Calib_time_DO06 PDM000_Response_DO06;
SIG_GROUP_ 2498698769 PDM000_Out_hs_05 1 : PDM000_SS_Step_DO05 PDM000_M_L_DO05 PDM000_Loss_of_COMM_DO05 PDM000_POR_command_DO05 PDM000_POR_En_DO05 PDM000_Command_type_DO05 PDM000_Motor_braking_DO05 PDM000_LSC_DO05 PDM000_Calib_time_DO05 PDM000_Response_DO05;
SIG_GROUP_ 2498698769 PDM000_Out_hs_04 1 : PDM000_SS_Step_DO04 PDM000_M_L_DO04 PDM000_Loss_of_COMM_DO04 PDM000_POR_command_DO04 PDM000_POR_En_DO04 PDM000_Command_type_DO04 PDM000_Motor_braking_DO04 PDM000_LSC_DO04 PDM000_Calib_time_DO04 PDM000_Response_DO04;
SIG_GROUP_ 2498698769 PDM000_Out_hs_03 1 : PDM000_SS_Step_DO03 PDM000_M_L_DO03 PDM000_Loss_of_COMM_DO03 PDM000_POR_command_DO03 PDM000_POR_En_DO03 PDM000_Command_type_DO03 PDM000_Motor_braking_DO03 PDM000_LSC_DO03 PDM000_Calib_time_DO03 PDM000_Response_DO03;
SIG_GROUP_ 2498698769 PDM000_Out_hs_02 1 : PDM000_SS_Step_DO02 PDM000_M_L_DO02 PDM000_Loss_of_COMM_DO02 PDM000_POR_command_DO02 PDM000_POR_En_DO02 PDM000_Command_type_DO02 PDM000_Motor_braking_DO02 PDM000_LSC_DO02 PDM000_Calib_time_DO02 PDM000_Response_DO02;
SIG_GROUP_ 2498698769 PDM000_Out_hs_01 1 : PDM000_SS_Step_DO01 PDM000_M_L_DO01 PDM000_Loss_of_COMM_DO01 PDM000_POR_command_DO01 PDM000_POR_En_DO01 PDM000_Command_type_DO01 PDM000_Motor_braking_DO01 PDM000_LSC_DO01 PDM000_Calib_time_DO01 PDM000_Response_DO01;
SIG_GROUP_ 2498698769 PDM004_CMD_Out01_06 1 : PDM004_CMD_DO01_PWM PDM004_CMD_DO02_PWM PDM004_CMD_DO03_PWM PDM004_CMD_DO04_PWM PDM004_CMD_DO05_PWM PDM004_CMD_DO06_PWM PDM004_CMD_DO01_EN PDM004_CMD_DO02_EN PDM004_CMD_DO03_EN PDM004_CMD_DO04_EN PDM004_CMD_DO05_EN PDM004_CMD_DO06_EN PDM004_CMD_tx_rate;
SIG_GROUP_ 2498698769 PDM005_CMD_Out07_12 1 : PDM005_CMD_DO07_PWM PDM005_CMD_DO08_PWM PDM005_CMD_DO09_PWM PDM005_CMD_DO10_PWM PDM005_CMD_DO11_PWM PDM005_CMD_DO12_PWM PDM005_CMD_DO07_EN PDM005_CMD_DO08_EN PDM005_CMD_DO09_EN PDM005_CMD_DO10_EN PDM005_CMD_DO11_EN PDM005_CMD_DO12_EN;
SIG_GROUP_ 2498698769 PDM007_Config_Out07_12 1 : PDM007_reserved_007 PDM007_HS_HB_DO09 PDM007_HS_HB_DO08 PDM007_HS_HB_DO07 PDM007_HS_HB_DO12 PDM007_HS_HB_DO11 PDM007_HS_HB_DO10 PDM007_Fb_type_DO09 PDM007_Fb_type_DO08 PDM007_Fb_type_DO07 PDM007_Fb_type_DO12 PDM007_Fb_type_DO11 PDM007_Fb_type_DO10 PDM007_CL_A_DO09 PDM007_CL_A_DO08 PDM007_CL_A_DO07 PDM007_CL_A_DO12 PDM007_CL_A_DO11 PDM007_CL_A_DO10 PDM007_Auto_reset_DO09 PDM007_Auto_reset_DO08 PDM007_Auto_reset_DO07 PDM007_Auto_reset_DO12 PDM007_Auto_reset_DO11 PDM007_Auto_reset_DO10;
SIG_GROUP_ 2498698769 PDM006_Config_Out01_06 1 : PDM006_reserved_006 PDM006_HS_HB_DO06 PDM006_HS_HB_DO05 PDM006_HS_HB_DO04 PDM006_HS_HB_DO03 PDM006_HS_HB_DO02 PDM006_HS_HB_DO01 PDM006_Fb_type_DO06 PDM006_Fb_type_DO05 PDM006_Fb_type_DO04 PDM006_Fb_type_DO03 PDM006_Fb_type_DO02 PDM006_Fb_type_DO01 PDM006_CL_A_DO06 PDM006_CL_A_DO05 PDM006_CL_A_DO04 PDM006_CL_A_DO03 PDM006_CL_A_DO02 PDM006_CL_A_DO01 PDM006_Auto_reset_DO06 PDM006_Auto_reset_DO05 PDM006_Auto_reset_DO04 PDM006_Auto_reset_DO03 PDM006_Auto_reset_DO02 PDM006_Auto_reset_DO01;
SIG_GROUP_ 2498695454 PDM134_Out_hs_12 1 : PDM134_SS_Step_DO12 PDM134_M_L_DO12 PDM134_Loss_of_COMM_DO12 PDM134_POR_command_DO12 PDM134_POR_En_DO12 PDM134_Command_type_DO12 PDM134_Motor_braking_DO12 PDM134_LSC_DO12 PDM134_Calib_time_DO12 PDM134_Response_DO12;
SIG_GROUP_ 2498695454 PDM134_Out_hs_11 1 : PDM134_SS_Step_DO11 PDM134_M_L_DO11 PDM134_Loss_of_COMM_DO11 PDM134_POR_command_DO11 PDM134_POR_En_DO11 PDM134_Command_type_DO11 PDM134_Motor_braking_DO11 PDM134_LSC_DO11 PDM134_Calib_time_DO11 PDM134_Response_DO11;
SIG_GROUP_ 2498695454 PDM134_Out_hs_10 1 : PDM134_SS_Step_DO10 PDM134_M_L_DO10 PDM134_Loss_of_COMM_DO10 PDM134_POR_command_DO10 PDM134_POR_En_DO10 PDM134_Command_type_DO10 PDM134_Motor_braking_DO10 PDM134_LSC_DO10 PDM134_Calib_time_DO10 PDM134_Response_DO10;
SIG_GROUP_ 2498695454 PDM134_Out_hs_09 1 : PDM134_SS_Step_DO09 PDM134_M_L_DO09 PDM134_Loss_of_COMM_DO09 PDM134_POR_command_DO09 PDM134_POR_En_DO09 PDM134_Command_type_DO09 PDM134_Motor_braking_DO09 PDM134_LSC_DO09 PDM134_Calib_time_DO09 PDM134_Response_DO09;
SIG_GROUP_ 2498695454 PDM134_Out_hs_08 1 : PDM134_SS_Step_DO08 PDM134_M_L_DO08 PDM134_Loss_of_COMM_DO08 PDM134_POR_command_DO08 PDM134_POR_En_DO08 PDM134_Command_type_DO08 PDM134_Motor_braking_DO08 PDM134_LSC_DO08 PDM134_Calib_time_DO08 PDM134_Response_DO08;
SIG_GROUP_ 2498695454 PDM134_Out_hs_07 1 : PDM134_SS_Step_DO07 PDM134_M_L_DO07 PDM134_Loss_of_COMM_DO07 PDM134_POR_command_DO07 PDM134_POR_En_DO07 PDM134_Command_type_DO07 PDM134_Motor_braking_DO07 PDM134_LSC_DO07 PDM134_Calib_time_DO07 PDM134_Response_DO07;
SIG_GROUP_ 2498695454 PDM134_Out_hs_06 1 : PDM134_SS_Step_DO06 PDM134_M_L_DO06 PDM134_Loss_of_COMM_DO06 PDM134_POR_command_DO06 PDM134_POR_En_DO06 PDM134_Command_type_DO06 PDM134_Motor_braking_DO06 PDM134_LSC_DO06 PDM134_Calib_time_DO06 PDM134_Response_DO06;
SIG_GROUP_ 2498695454 PDM134_Out_hs_05 1 : PDM134_SS_Step_DO05 PDM134_M_L_DO05 PDM134_Loss_of_COMM_DO05 PDM134_POR_command_DO05 PDM134_POR_En_DO05 PDM134_Command_type_DO05 PDM134_Motor_braking_DO05 PDM134_LSC_DO05 PDM134_Calib_time_DO05 PDM134_Response_DO05;
SIG_GROUP_ 2498695454 PDM134_Out_hs_04 1 : PDM134_SS_Step_DO04 PDM134_M_L_DO04 PDM134_Loss_of_COMM_DO04 PDM134_POR_command_DO04 PDM134_POR_En_DO04 PDM134_Command_type_DO04 PDM134_Motor_braking_DO04 PDM134_LSC_DO04 PDM134_Calib_time_DO04 PDM134_Response_DO04;
SIG_GROUP_ 2498695454 PDM134_Out_hs_03 1 : PDM134_SS_Step_DO03 PDM134_M_L_DO03 PDM134_Loss_of_COMM_DO03 PDM134_POR_command_DO03 PDM134_POR_En_DO03 PDM134_Command_type_DO03 PDM134_Motor_braking_DO03 PDM134_LSC_DO03 PDM134_Calib_time_DO03 PDM134_Response_DO03;
SIG_GROUP_ 2498695454 PDM134_Out_hs_02 1 : PDM134_SS_Step_DO02 PDM134_M_L_DO02 PDM134_Loss_of_COMM_DO02 PDM134_POR_command_DO02 PDM134_POR_En_DO02 PDM134_Command_type_DO02 PDM134_Motor_braking_DO02 PDM134_LSC_DO02 PDM134_Calib_time_DO02 PDM134_Response_DO02;
SIG_GROUP_ 2498695454 PDM134_Out_hs_01 1 : PDM134_SS_Step_DO01 PDM134_M_L_DO01 PDM134_Loss_of_COMM_DO01 PDM134_POR_command_DO01 PDM134_POR_En_DO01 PDM134_Command_type_DO01 PDM134_Motor_braking_DO01 PDM134_LSC_DO01 PDM134_Calib_time_DO01 PDM134_Response_DO01;
SIG_GROUP_ 2498695454 PDM136_Config_hs_Out07_12 1 : PDM136_reserved_136 PDM136_HS_HB_DO09 PDM136_HS_HB_DO08 PDM136_HS_HB_DO07 PDM136_HS_HB_DO12 PDM136_HS_HB_DO11 PDM136_HS_HB_DO10 PDM136_Fb_type_DO09 PDM136_Fb_type_DO08 PDM136_Fb_type_DO07 PDM136_Fb_type_DO12 PDM136_Fb_type_DO11 PDM136_Fb_type_DO10 PDM136_CL_A_DO09 PDM136_CL_A_DO08 PDM136_CL_A_DO07 PDM136_CL_A_DO12 PDM136_CL_A_DO11 PDM136_CL_A_DO10 PDM136_Auto_reset_DO09 PDM136_Auto_reset_DO08 PDM136_Auto_reset_DO07 PDM136_Auto_reset_DO12 PDM136_Auto_reset_DO11 PDM136_Auto_reset_DO10;
SIG_GROUP_ 2498695454 PDM135_Config_hs_Out01_06 1 : PDM135_reserved_135 PDM135_HS_HB_DO06 PDM135_HS_HB_DO05 PDM135_HS_HB_DO04 PDM135_HS_HB_DO03 PDM135_HS_HB_DO02 PDM135_HS_HB_DO01 PDM135_Fb_type_DO06 PDM135_Fb_type_DO05 PDM135_Fb_type_DO04 PDM135_Fb_type_DO03 PDM135_Fb_type_DO02 PDM135_Fb_type_DO01 PDM135_CL_A_DO06 PDM135_CL_A_DO05 PDM135_CL_A_DO04 PDM135_CL_A_DO03 PDM135_CL_A_DO02 PDM135_CL_A_DO01 PDM135_Auto_reset_DO06 PDM135_Auto_reset_DO05 PDM135_Auto_reset_DO04 PDM135_Auto_reset_DO03 PDM135_Auto_reset_DO02 PDM135_Auto_reset_DO01;
SIG_GROUP_ 2498695454 PDM133_Outputs_07_12_fb 1 : PDM133_DO09_current_A PDM133_DO08_current_A PDM133_DO07_current_A PDM133_DO12_current_A PDM133_DO11_current_A PDM133_DO10_current_A;
SIG_GROUP_ 2498695454 PDM132_Outputs_01_06_fb 1 : PDM132_DO06_current_A PDM132_DO05_current_A PDM132_DO04_current_A PDM132_DO03_current_A PDM132_DO02_current_A PDM132_DO01_current_A;
SIG_GROUP_ 2498695454 PDM131_A7_A8_sw_pwr_supply 1 : PDM131_Total_current_status PDM131_Software_rev PDM131_Power_supply_status PDM131_AI8_V PDM131_AI7_V;
SIG_GROUP_ 2498695454 PDM130_A5_A6_Batt 1 : PDM130_Sensor_supply_low PDM130_Sensor_supply_high PDM130_reserved_130 PDM130_Battery_voltage PDM130_AI6_V PDM130_AI5_V;
SIG_GROUP_ 2498695454 PDM129_A3_A4_ODiag 1 : PDM129_Diag_DO12 PDM129_Diag_DO11 PDM129_Diag_DO10 PDM129_Diag_DO09 PDM129_Diag_DO08 PDM129_Diag_DO07 PDM129_Diag_DO06 PDM129_Diag_DO05 PDM129_Diag_DO04 PDM129_Diag_DO03 PDM129_Diag_DO02 PDM129_Diag_DO01 PDM129_AI4_V PDM129_AI3_V;
SIG_GROUP_ 2498695454 PDM128_A1_A2_D1_D12 1 : PDM128_DI12 PDM128_DI11 PDM128_DI10 PDM128_DI09 PDM128_DI08 PDM128_DI07 PDM128_DI06 PDM128_DI05 PDM128_DI04 PDM128_DI03 PDM128_DI02 PDM128_AI2_Ohm PDM128_AI1_Ohm PDM128_DI01;

SG_MUL_VAL_ 2498698769 PDM000_Output_Channel PDM_MULTIP_1 0-0;
SG_MUL_VAL_ 2498698769 PDM000_SS_Step_DO01 PDM000_Output_Channel 1-1;
SG_MUL_VAL_ 2498698769 PDM000_M_L_DO01 PDM000_Output_Channel 1-1;
SG_MUL_VAL_ 2498698769 PDM000_Loss_of_COMM_DO01 PDM000_Output_Channel 1-1;
SG_MUL_VAL_ 2498698769 PDM000_POR_command_DO01 PDM000_Output_Channel 1-1;
SG_MUL_VAL_ 2498698769 PDM000_POR_En_DO01 PDM000_Output_Channel 1-1;
SG_MUL_VAL_ 2498698769 PDM000_Command_type_DO01 PDM000_Output_Channel 1-1;
SG_MUL_VAL_ 2498698769 PDM000_Motor_braking_DO01 PDM000_Output_Channel 1-1;
SG_MUL_VAL_ 2498698769 PDM000_LSC_DO01 PDM000_Output_Channel 1-1;
SG_MUL_VAL_ 2498698769 PDM000_Calib_time_DO01 PDM000_Output_Channel 1-1;
SG_MUL_VAL_ 2498698769 PDM000_Response_DO01 PDM000_Output_Channel 1-1;
SG_MUL_VAL_ 2498698769 PDM000_SS_Step_DO02 PDM000_Output_Channel 2-2;
SG_MUL_VAL_ 2498698769 PDM000_M_L_DO02 PDM000_Output_Channel 2-2;
SG_MUL_VAL_ 2498698769 PDM000_Loss_of_COMM_DO02 PDM000_Output_Channel 2-2;
SG_MUL_VAL_ 2498698769 PDM000_POR_command_DO02 PDM000_Output_Channel 2-2;
SG_MUL_VAL_ 2498698769 PDM000_POR_En_DO02 PDM000_Output_Channel 2-2;
SG_MUL_VAL_ 2498698769 PDM000_Command_type_DO02 PDM000_Output_Channel 2-2;
SG_MUL_VAL_ 2498698769 PDM000_Motor_braking_DO02 PDM000_Output_Channel 2-2;
SG_MUL_VAL_ 2498698769 PDM000_LSC_DO02 PDM000_Output_Channel 2-2;
SG_MUL_VAL_ 2498698769 PDM000_Calib_time_DO02 PDM000_Output_Channel 2-2;
SG_MUL_VAL_ 2498698769 PDM000_Response_DO02 PDM000_Output_Channel 2-2;
SG_MUL_VAL_ 2498698769 PDM000_SS_Step_DO03 PDM000_Output_Channel 3-3;
SG_MUL_VAL_ 2498698769 PDM000_M_L_DO03 PDM000_Output_Channel 3-3;
SG_MUL_VAL_ 2498698769 PDM000_Loss_of_COMM_DO03 PDM000_Output_Channel 3-3;
SG_MUL_VAL_ 2498698769 PDM000_POR_command_DO03 PDM000_Output_Channel 3-3;
SG_MUL_VAL_ 2498698769 PDM000_POR_En_DO03 PDM000_Output_Channel 3-3;
SG_MUL_VAL_ 2498698769 PDM000_Command_type_DO03 PDM000_Output_Channel 3-3;
SG_MUL_VAL_ 2498698769 PDM000_Motor_braking_DO03 PDM000_Output_Channel 3-3;
SG_MUL_VAL_ 2498698769 PDM000_LSC_DO03 PDM000_Output_Channel 3-3;
SG_MUL_VAL_ 2498698769 PDM000_Calib_time_DO03 PDM000_Output_Channel 3-3;
SG_MUL_VAL_ 2498698769 PDM000_Response_DO03 PDM000_Output_Channel 3-3;
SG_MUL_VAL_ 2498698769 PDM000_SS_Step_DO04 PDM000_Output_Channel 4-4;
SG_MUL_VAL_ 2498698769 PDM000_M_L_DO04 PDM000_Output_Channel 4-4;
SG_MUL_VAL_ 2498698769 PDM000_Loss_of_COMM_DO04 PDM000_Output_Channel 4-4;
SG_MUL_VAL_ 2498698769 PDM000_POR_command_DO04 PDM000_Output_Channel 4-4;
SG_MUL_VAL_ 2498698769 PDM000_POR_En_DO04 PDM000_Output_Channel 4-4;
SG_MUL_VAL_ 2498698769 PDM000_Command_type_DO04 PDM000_Output_Channel 4-4;
SG_MUL_VAL_ 2498698769 PDM000_Motor_braking_DO04 PDM000_Output_Channel 4-4;
SG_MUL_VAL_ 2498698769 PDM000_LSC_DO04 PDM000_Output_Channel 4-4;
SG_MUL_VAL_ 2498698769 PDM000_Calib_time_DO04 PDM000_Output_Channel 4-4;
SG_MUL_VAL_ 2498698769 PDM000_Response_DO04 PDM000_Output_Channel 4-4;
SG_MUL_VAL_ 2498698769 PDM000_SS_Step_DO05 PDM000_Output_Channel 5-5;
SG_MUL_VAL_ 2498698769 PDM000_M_L_DO05 PDM000_Output_Channel 5-5;
SG_MUL_VAL_ 2498698769 PDM000_Loss_of_COMM_DO05 PDM000_Output_Channel 5-5;
SG_MUL_VAL_ 2498698769 PDM000_POR_command_DO05 PDM000_Output_Channel 5-5;
SG_MUL_VAL_ 2498698769 PDM000_POR_En_DO05 PDM000_Output_Channel 5-5;
SG_MUL_VAL_ 2498698769 PDM000_Command_type_DO05 PDM000_Output_Channel 5-5;
SG_MUL_VAL_ 2498698769 PDM000_Motor_braking_DO05 PDM000_Output_Channel 5-5;
SG_MUL_VAL_ 2498698769 PDM000_LSC_DO05 PDM000_Output_Channel 5-5;
SG_MUL_VAL_ 2498698769 PDM000_Calib_time_DO05 PDM000_Output_Channel 5-5;
SG_MUL_VAL_ 2498698769 PDM000_Response_DO05 PDM000_Output_Channel 5-5;
SG_MUL_VAL_ 2498698769 PDM000_SS_Step_DO06 PDM000_Output_Channel 6-6;
SG_MUL_VAL_ 2498698769 PDM000_M_L_DO06 PDM000_Output_Channel 6-6;
SG_MUL_VAL_ 2498698769 PDM000_Loss_of_COMM_DO06 PDM000_Output_Channel 6-6;
SG_MUL_VAL_ 2498698769 PDM000_POR_command_DO06 PDM000_Output_Channel 6-6;
SG_MUL_VAL_ 2498698769 PDM000_POR_En_DO06 PDM000_Output_Channel 6-6;
SG_MUL_VAL_ 2498698769 PDM000_Command_type_DO06 PDM000_Output_Channel 6-6;
SG_MUL_VAL_ 2498698769 PDM000_Motor_braking_DO06 PDM000_Output_Channel 6-6;
SG_MUL_VAL_ 2498698769 PDM000_LSC_DO06 PDM000_Output_Channel 6-6;
SG_MUL_VAL_ 2498698769 PDM000_Calib_time_DO06 PDM000_Output_Channel 6-6;
SG_MUL_VAL_ 2498698769 PDM000_Response_DO06 PDM000_Output_Channel 6-6;
SG_MUL_VAL_ 2498698769 PDM000_SS_Step_DO07 PDM000_Output_Channel 7-7;
SG_MUL_VAL_ 2498698769 PDM000_M_L_DO07 PDM000_Output_Channel 7-7;
SG_MUL_VAL_ 2498698769 PDM000_Loss_of_COMM_DO07 PDM000_Output_Channel 7-7;
SG_MUL_VAL_ 2498698769 PDM000_POR_command_DO07 PDM000_Output_Channel 7-7;
SG_MUL_VAL_ 2498698769 PDM000_POR_En_DO07 PDM000_Output_Channel 7-7;
SG_MUL_VAL_ 2498698769 PDM000_Command_type_DO07 PDM000_Output_Channel 7-7;
SG_MUL_VAL_ 2498698769 PDM000_Motor_braking_DO07 PDM000_Output_Channel 7-7;
SG_MUL_VAL_ 2498698769 PDM000_LSC_DO07 PDM000_Output_Channel 7-7;
SG_MUL_VAL_ 2498698769 PDM000_Calib_time_DO07 PDM000_Output_Channel 7-7;
SG_MUL_VAL_ 2498698769 PDM000_Response_DO07 PDM000_Output_Channel 7-7;
SG_MUL_VAL_ 2498698769 PDM000_SS_Step_DO08 PDM000_Output_Channel 8-8;
SG_MUL_VAL_ 2498698769 PDM000_M_L_DO08 PDM000_Output_Channel 8-8;
SG_MUL_VAL_ 2498698769 PDM000_Loss_of_COMM_DO08 PDM000_Output_Channel 8-8;
SG_MUL_VAL_ 2498698769 PDM000_POR_command_DO08 PDM000_Output_Channel 8-8;
SG_MUL_VAL_ 2498698769 PDM000_POR_En_DO08 PDM000_Output_Channel 8-8;
SG_MUL_VAL_ 2498698769 PDM000_Command_type_DO08 PDM000_Output_Channel 8-8;
SG_MUL_VAL_ 2498698769 PDM000_Motor_braking_DO08 PDM000_Output_Channel 8-8;
SG_MUL_VAL_ 2498698769 PDM000_LSC_DO08 PDM000_Output_Channel 8-8;
SG_MUL_VAL_ 2498698769 PDM000_Calib_time_DO08 PDM000_Output_Channel 8-8;
SG_MUL_VAL_ 2498698769 PDM000_Response_DO08 PDM000_Output_Channel 8-8;
SG_MUL_VAL_ 2498698769 PDM000_SS_Step_DO09 PDM000_Output_Channel 9-9;
SG_MUL_VAL_ 2498698769 PDM000_M_L_DO09 PDM000_Output_Channel 9-9;
SG_MUL_VAL_ 2498698769 PDM000_Loss_of_COMM_DO09 PDM000_Output_Channel 9-9;
SG_MUL_VAL_ 2498698769 PDM000_POR_command_DO09 PDM000_Output_Channel 9-9;
SG_MUL_VAL_ 2498698769 PDM000_POR_En_DO09 PDM000_Output_Channel 9-9;
SG_MUL_VAL_ 2498698769 PDM000_Command_type_DO09 PDM000_Output_Channel 9-9;
SG_MUL_VAL_ 2498698769 PDM000_Motor_braking_DO09 PDM000_Output_Channel 9-9;
SG_MUL_VAL_ 2498698769 PDM000_LSC_DO09 PDM000_Output_Channel 9-9;
SG_MUL_VAL_ 2498698769 PDM000_Calib_time_DO09 PDM000_Output_Channel 9-9;
SG_MUL_VAL_ 2498698769 PDM000_Response_DO09 PDM000_Output_Channel 9-9;
SG_MUL_VAL_ 2498698769 PDM000_SS_Step_DO10 PDM000_Output_Channel 10-10;
SG_MUL_VAL_ 2498698769 PDM000_M_L_DO10 PDM000_Output_Channel 10-10;
SG_MUL_VAL_ 2498698769 PDM000_Loss_of_COMM_DO10 PDM000_Output_Channel 10-10;
SG_MUL_VAL_ 2498698769 PDM000_POR_command_DO10 PDM000_Output_Channel 10-10;
SG_MUL_VAL_ 2498698769 PDM000_POR_En_DO10 PDM000_Output_Channel 10-10;
SG_MUL_VAL_ 2498698769 PDM000_Command_type_DO10 PDM000_Output_Channel 10-10;
SG_MUL_VAL_ 2498698769 PDM000_Motor_braking_DO10 PDM000_Output_Channel 10-10;
SG_MUL_VAL_ 2498698769 PDM000_LSC_DO10 PDM000_Output_Channel 10-10;
SG_MUL_VAL_ 2498698769 PDM000_Calib_time_DO10 PDM000_Output_Channel 10-10;
SG_MUL_VAL_ 2498698769 PDM000_Response_DO10 PDM000_Output_Channel 10-10;
SG_MUL_VAL_ 2498698769 PDM000_SS_Step_DO11 PDM000_Output_Channel 11-11;
SG_MUL_VAL_ 2498698769 PDM000_M_L_DO11 PDM000_Output_Channel 11-11;
SG_MUL_VAL_ 2498698769 PDM000_Loss_of_COMM_DO11 PDM000_Output_Channel 11-11;
SG_MUL_VAL_ 2498698769 PDM000_POR_command_DO11 PDM000_Output_Channel 11-11;
SG_MUL_VAL_ 2498698769 PDM000_POR_En_DO11 PDM000_Output_Channel 11-11;
SG_MUL_VAL_ 2498698769 PDM000_Command_type_DO11 PDM000_Output_Channel 11-11;
SG_MUL_VAL_ 2498698769 PDM000_Motor_braking_DO11 PDM000_Output_Channel 11-11;
SG_MUL_VAL_ 2498698769 PDM000_LSC_DO11 PDM000_Output_Channel 11-11;
SG_MUL_VAL_ 2498698769 PDM000_Calib_time_DO11 PDM000_Output_Channel 11-11;
SG_MUL_VAL_ 2498698769 PDM000_Response_DO11 PDM000_Output_Channel 11-11;
SG_MUL_VAL_ 2498698769 PDM000_SS_Step_DO12 PDM000_Output_Channel 12-12;
SG_MUL_VAL_ 2498698769 PDM000_M_L_DO12 PDM000_Output_Channel 12-12;
SG_MUL_VAL_ 2498698769 PDM000_Loss_of_COMM_DO12 PDM000_Output_Channel 12-12;
SG_MUL_VAL_ 2498698769 PDM000_POR_command_DO12 PDM000_Output_Channel 12-12;
SG_MUL_VAL_ 2498698769 PDM000_POR_En_DO12 PDM000_Output_Channel 12-12;
SG_MUL_VAL_ 2498698769 PDM000_Command_type_DO12 PDM000_Output_Channel 12-12;
SG_MUL_VAL_ 2498698769 PDM000_Motor_braking_DO12 PDM000_Output_Channel 12-12;
SG_MUL_VAL_ 2498698769 PDM000_LSC_DO12 PDM000_Output_Channel 12-12;
SG_MUL_VAL_ 2498698769 PDM000_Calib_time_DO12 PDM000_Output_Channel 12-12;
SG_MUL_VAL_ 2498698769 PDM000_Response_DO12 PDM000_Output_Channel 12-12;
SG_MUL_VAL_ 2498698769 PDM004_CMD_DO01_PWM PDM_MULTIP_1 4-4;
SG_MUL_VAL_ 2498698769 PDM004_CMD_DO02_PWM PDM_MULTIP_1 4-4;
SG_MUL_VAL_ 2498698769 PDM004_CMD_DO03_PWM PDM_MULTIP_1 4-4;
SG_MUL_VAL_ 2498698769 PDM004_CMD_DO04_PWM PDM_MULTIP_1 4-4;
SG_MUL_VAL_ 2498698769 PDM004_CMD_DO05_PWM PDM_MULTIP_1 4-4;
SG_MUL_VAL_ 2498698769 PDM004_CMD_DO06_PWM PDM_MULTIP_1 4-4;
SG_MUL_VAL_ 2498698769 PDM004_CMD_DO01_EN PDM_MULTIP_1 4-4;
SG_MUL_VAL_ 2498698769 PDM004_CMD_DO02_EN PDM_MULTIP_1 4-4;
SG_MUL_VAL_ 2498698769 PDM004_CMD_DO03_EN PDM_MULTIP_1 4-4;
SG_MUL_VAL_ 2498698769 PDM004_CMD_DO04_EN PDM_MULTIP_1 4-4;
SG_MUL_VAL_ 2498698769 PDM004_CMD_DO05_EN PDM_MULTIP_1 4-4;
SG_MUL_VAL_ 2498698769 PDM004_CMD_DO06_EN PDM_MULTIP_1 4-4;
SG_MUL_VAL_ 2498698769 PDM004_CMD_tx_rate PDM_MULTIP_1 4-4;
SG_MUL_VAL_ 2498698769 PDM005_CMD_DO07_PWM PDM_MULTIP_1 5-5;
SG_MUL_VAL_ 2498698769 PDM005_CMD_DO08_PWM PDM_MULTIP_1 5-5;
SG_MUL_VAL_ 2498698769 PDM005_CMD_DO09_PWM PDM_MULTIP_1 5-5;
SG_MUL_VAL_ 2498698769 PDM005_CMD_DO10_PWM PDM_MULTIP_1 5-5;
SG_MUL_VAL_ 2498698769 PDM005_CMD_DO11_PWM PDM_MULTIP_1 5-5;
SG_MUL_VAL_ 2498698769 PDM005_CMD_DO12_PWM PDM_MULTIP_1 5-5;
SG_MUL_VAL_ 2498698769 PDM005_CMD_DO07_EN PDM_MULTIP_1 5-5;
SG_MUL_VAL_ 2498698769 PDM005_CMD_DO08_EN PDM_MULTIP_1 5-5;
SG_MUL_VAL_ 2498698769 PDM005_CMD_DO09_EN PDM_MULTIP_1 5-5;
SG_MUL_VAL_ 2498698769 PDM005_CMD_DO10_EN PDM_MULTIP_1 5-5;
SG_MUL_VAL_ 2498698769 PDM005_CMD_DO11_EN PDM_MULTIP_1 5-5;
SG_MUL_VAL_ 2498698769 PDM005_CMD_DO12_EN PDM_MULTIP_1 5-5;
SG_MUL_VAL_ 2498698769 PDM006_CL_A_DO01 PDM_MULTIP_1 6-6;
SG_MUL_VAL_ 2498698769 PDM006_Fb_type_DO01 PDM_MULTIP_1 6-6;
SG_MUL_VAL_ 2498698769 PDM006_Auto_reset_DO01 PDM_MULTIP_1 6-6;
SG_MUL_VAL_ 2498698769 PDM006_HS_HB_DO01 PDM_MULTIP_1 6-6;
SG_MUL_VAL_ 2498698769 PDM006_CL_A_DO02 PDM_MULTIP_1 6-6;
SG_MUL_VAL_ 2498698769 PDM006_Fb_type_DO02 PDM_MULTIP_1 6-6;
SG_MUL_VAL_ 2498698769 PDM006_Auto_reset_DO02 PDM_MULTIP_1 6-6;
SG_MUL_VAL_ 2498698769 PDM006_HS_HB_DO02 PDM_MULTIP_1 6-6;
SG_MUL_VAL_ 2498698769 PDM006_CL_A_DO03 PDM_MULTIP_1 6-6;
SG_MUL_VAL_ 2498698769 PDM006_Fb_type_DO03 PDM_MULTIP_1 6-6;
SG_MUL_VAL_ 2498698769 PDM006_Auto_reset_DO03 PDM_MULTIP_1 6-6;
SG_MUL_VAL_ 2498698769 PDM006_HS_HB_DO03 PDM_MULTIP_1 6-6;
SG_MUL_VAL_ 2498698769 PDM006_CL_A_DO04 PDM_MULTIP_1 6-6;
SG_MUL_VAL_ 2498698769 PDM006_Fb_type_DO04 PDM_MULTIP_1 6-6;
SG_MUL_VAL_ 2498698769 PDM006_Auto_reset_DO04 PDM_MULTIP_1 6-6;
SG_MUL_VAL_ 2498698769 PDM006_HS_HB_DO04 PDM_MULTIP_1 6-6;
SG_MUL_VAL_ 2498698769 PDM006_CL_A_DO05 PDM_MULTIP_1 6-6;
SG_MUL_VAL_ 2498698769 PDM006_Fb_type_DO05 PDM_MULTIP_1 6-6;
SG_MUL_VAL_ 2498698769 PDM006_Auto_reset_DO05 PDM_MULTIP_1 6-6;
SG_MUL_VAL_ 2498698769 PDM006_HS_HB_DO05 PDM_MULTIP_1 6-6;
SG_MUL_VAL_ 2498698769 PDM006_CL_A_DO06 PDM_MULTIP_1 6-6;
SG_MUL_VAL_ 2498698769 PDM006_Fb_type_DO06 PDM_MULTIP_1 6-6;
SG_MUL_VAL_ 2498698769 PDM006_Auto_reset_DO06 PDM_MULTIP_1 6-6;
SG_MUL_VAL_ 2498698769 PDM006_HS_HB_DO06 PDM_MULTIP_1 6-6;
SG_MUL_VAL_ 2498698769 PDM006_reserved_006 PDM_MULTIP_1 6-6;
SG_MUL_VAL_ 2498698769 PDM007_CL_A_DO07 PDM_MULTIP_1 7-7;
SG_MUL_VAL_ 2498698769 PDM007_Fb_type_DO07 PDM_MULTIP_1 7-7;
SG_MUL_VAL_ 2498698769 PDM007_Auto_reset_DO07 PDM_MULTIP_1 7-7;
SG_MUL_VAL_ 2498698769 PDM007_HS_HB_DO07 PDM_MULTIP_1 7-7;
SG_MUL_VAL_ 2498698769 PDM007_CL_A_DO08 PDM_MULTIP_1 7-7;
SG_MUL_VAL_ 2498698769 PDM007_Fb_type_DO08 PDM_MULTIP_1 7-7;
SG_MUL_VAL_ 2498698769 PDM007_Auto_reset_DO08 PDM_MULTIP_1 7-7;
SG_MUL_VAL_ 2498698769 PDM007_HS_HB_DO08 PDM_MULTIP_1 7-7;
SG_MUL_VAL_ 2498698769 PDM007_CL_A_DO09 PDM_MULTIP_1 7-7;
SG_MUL_VAL_ 2498698769 PDM007_Fb_type_DO09 PDM_MULTIP_1 7-7;
SG_MUL_VAL_ 2498698769 PDM007_Auto_reset_DO09 PDM_MULTIP_1 7-7;
SG_MUL_VAL_ 2498698769 PDM007_HS_HB_DO09 PDM_MULTIP_1 7-7;
SG_MUL_VAL_ 2498698769 PDM007_CL_A_DO10 PDM_MULTIP_1 7-7;
SG_MUL_VAL_ 2498698769 PDM007_Fb_type_DO10 PDM_MULTIP_1 7-7;
SG_MUL_VAL_ 2498698769 PDM007_Auto_reset_DO10 PDM_MULTIP_1 7-7;
SG_MUL_VAL_ 2498698769 PDM007_HS_HB_DO10 PDM_MULTIP_1 7-7;
SG_MUL_VAL_ 2498698769 PDM007_CL_A_DO11 PDM_MULTIP_1 7-7;
SG_MUL_VAL_ 2498698769 PDM007_Fb_type_DO11 PDM_MULTIP_1 7-7;
SG_MUL_VAL_ 2498698769 PDM007_Auto_reset_DO11 PDM_MULTIP_1 7-7;
SG_MUL_VAL_ 2498698769 PDM007_HS_HB_DO11 PDM_MULTIP_1 7-7;
SG_MUL_VAL_ 2498698769 PDM007_CL_A_DO12 PDM_MULTIP_1 7-7;
SG_MUL_VAL_ 2498698769 PDM007_Fb_type_DO12 PDM_MULTIP_1 7-7;
SG_MUL_VAL_ 2498698769 PDM007_Auto_reset_DO12 PDM_MULTIP_1 7-7;
SG_MUL_VAL_ 2498698769 PDM007_HS_HB_DO12 PDM_MULTIP_1 7-7;
SG_MUL_VAL_ 2498698769 PDM007_reserved_007 PDM_MULTIP_1 7-7;
SG_MUL_VAL_ 2498695454 PDM134_Output_Channel PDM_MULTIP_0 134-134;
SG_MUL_VAL_ 2498695454 PDM128_DI01 PDM_MULTIP_0 128-128;
SG_MUL_VAL_ 2498695454 PDM128_DI02 PDM_MULTIP_0 128-128;
SG_MUL_VAL_ 2498695454 PDM128_DI03 PDM_MULTIP_0 128-128;
SG_MUL_VAL_ 2498695454 PDM128_DI04 PDM_MULTIP_0 128-128;
SG_MUL_VAL_ 2498695454 PDM128_DI05 PDM_MULTIP_0 128-128;
SG_MUL_VAL_ 2498695454 PDM128_DI06 PDM_MULTIP_0 128-128;
SG_MUL_VAL_ 2498695454 PDM128_DI07 PDM_MULTIP_0 128-128;
SG_MUL_VAL_ 2498695454 PDM128_DI08 PDM_MULTIP_0 128-128;
SG_MUL_VAL_ 2498695454 PDM128_DI09 PDM_MULTIP_0 128-128;
SG_MUL_VAL_ 2498695454 PDM128_DI10 PDM_MULTIP_0 128-128;
SG_MUL_VAL_ 2498695454 PDM128_DI11 PDM_MULTIP_0 128-128;
SG_MUL_VAL_ 2498695454 PDM128_DI12 PDM_MULTIP_0 128-128;
SG_MUL_VAL_ 2498695454 PDM128_AI1_Ohm PDM_MULTIP_0 128-128;
SG_MUL_VAL_ 2498695454 PDM128_AI2_Ohm PDM_MULTIP_0 128-128;
SG_MUL_VAL_ 2498695454 PDM129_Diag_DO01 PDM_MULTIP_0 129-129;
SG_MUL_VAL_ 2498695454 PDM129_Diag_DO02 PDM_MULTIP_0 129-129;
SG_MUL_VAL_ 2498695454 PDM129_Diag_DO03 PDM_MULTIP_0 129-129;
SG_MUL_VAL_ 2498695454 PDM129_Diag_DO04 PDM_MULTIP_0 129-129;
SG_MUL_VAL_ 2498695454 PDM129_Diag_DO05 PDM_MULTIP_0 129-129;
SG_MUL_VAL_ 2498695454 PDM129_Diag_DO06 PDM_MULTIP_0 129-129;
SG_MUL_VAL_ 2498695454 PDM129_Diag_DO07 PDM_MULTIP_0 129-129;
SG_MUL_VAL_ 2498695454 PDM129_Diag_DO08 PDM_MULTIP_0 129-129;
SG_MUL_VAL_ 2498695454 PDM129_Diag_DO09 PDM_MULTIP_0 129-129;
SG_MUL_VAL_ 2498695454 PDM129_Diag_DO10 PDM_MULTIP_0 129-129;
SG_MUL_VAL_ 2498695454 PDM129_Diag_DO11 PDM_MULTIP_0 129-129;
SG_MUL_VAL_ 2498695454 PDM129_Diag_DO12 PDM_MULTIP_0 129-129;
SG_MUL_VAL_ 2498695454 PDM129_AI3_V PDM_MULTIP_0 129-129;
SG_MUL_VAL_ 2498695454 PDM129_AI4_V PDM_MULTIP_0 129-129;
SG_MUL_VAL_ 2498695454 PDM130_reserved_130 PDM_MULTIP_0 130-130;
SG_MUL_VAL_ 2498695454 PDM130_Sensor_supply_high PDM_MULTIP_0 130-130;
SG_MUL_VAL_ 2498695454 PDM130_Sensor_supply_low PDM_MULTIP_0 130-130;
SG_MUL_VAL_ 2498695454 PDM130_Battery_voltage PDM_MULTIP_0 130-130;
SG_MUL_VAL_ 2498695454 PDM130_AI5_V PDM_MULTIP_0 130-130;
SG_MUL_VAL_ 2498695454 PDM130_AI6_V PDM_MULTIP_0 130-130;
SG_MUL_VAL_ 2498695454 PDM131_Power_supply_status PDM_MULTIP_0 131-131;
SG_MUL_VAL_ 2498695454 PDM131_Total_current_status PDM_MULTIP_0 131-131;
SG_MUL_VAL_ 2498695454 PDM131_Software_rev PDM_MULTIP_0 131-131;
SG_MUL_VAL_ 2498695454 PDM131_AI7_V PDM_MULTIP_0 131-131;
SG_MUL_VAL_ 2498695454 PDM131_AI8_V PDM_MULTIP_0 131-131;
SG_MUL_VAL_ 2498695454 PDM132_DO01_current_A PDM_MULTIP_0 132-132;
SG_MUL_VAL_ 2498695454 PDM132_DO02_current_A PDM_MULTIP_0 132-132;
SG_MUL_VAL_ 2498695454 PDM132_DO03_current_A PDM_MULTIP_0 132-132;
SG_MUL_VAL_ 2498695454 PDM132_DO04_current_A PDM_MULTIP_0 132-132;
SG_MUL_VAL_ 2498695454 PDM132_DO05_current_A PDM_MULTIP_0 132-132;
SG_MUL_VAL_ 2498695454 PDM132_DO06_current_A PDM_MULTIP_0 132-132;
SG_MUL_VAL_ 2498695454 PDM133_DO07_current_A PDM_MULTIP_0 133-133;
SG_MUL_VAL_ 2498695454 PDM133_DO08_current_A PDM_MULTIP_0 133-133;
SG_MUL_VAL_ 2498695454 PDM133_DO09_current_A PDM_MULTIP_0 133-133;
SG_MUL_VAL_ 2498695454 PDM133_DO10_current_A PDM_MULTIP_0 133-133;
SG_MUL_VAL_ 2498695454 PDM133_DO11_current_A PDM_MULTIP_0 133-133;
SG_MUL_VAL_ 2498695454 PDM133_DO12_current_A PDM_MULTIP_0 133-133;
SG_MUL_VAL_ 2498695454 PDM134_SS_Step_DO01 PDM134_Output_Channel 1-1;
SG_MUL_VAL_ 2498695454 PDM134_M_L_DO01 PDM134_Output_Channel 1-1;
SG_MUL_VAL_ 2498695454 PDM134_Loss_of_COMM_DO01 PDM134_Output_Channel 1-1;
SG_MUL_VAL_ 2498695454 PDM134_POR_command_DO01 PDM134_Output_Channel 1-1;
SG_MUL_VAL_ 2498695454 PDM134_POR_En_DO01 PDM134_Output_Channel 1-1;
SG_MUL_VAL_ 2498695454 PDM134_Command_type_DO01 PDM134_Output_Channel 1-1;
SG_MUL_VAL_ 2498695454 PDM134_Motor_braking_DO01 PDM134_Output_Channel 1-1;
SG_MUL_VAL_ 2498695454 PDM134_LSC_DO01 PDM134_Output_Channel 1-1;
SG_MUL_VAL_ 2498695454 PDM134_Calib_time_DO01 PDM134_Output_Channel 1-1;
SG_MUL_VAL_ 2498695454 PDM134_Response_DO01 PDM134_Output_Channel 1-1;
SG_MUL_VAL_ 2498695454 PDM134_SS_Step_DO02 PDM134_Output_Channel 2-2;
SG_MUL_VAL_ 2498695454 PDM134_M_L_DO02 PDM134_Output_Channel 2-2;
SG_MUL_VAL_ 2498695454 PDM134_Loss_of_COMM_DO02 PDM134_Output_Channel 2-2;
SG_MUL_VAL_ 2498695454 PDM134_POR_command_DO02 PDM134_Output_Channel 2-2;
SG_MUL_VAL_ 2498695454 PDM134_POR_En_DO02 PDM134_Output_Channel 2-2;
SG_MUL_VAL_ 2498695454 PDM134_Command_type_DO02 PDM134_Output_Channel 2-2;
SG_MUL_VAL_ 2498695454 PDM134_Motor_braking_DO02 PDM134_Output_Channel 2-2;
SG_MUL_VAL_ 2498695454 PDM134_LSC_DO02 PDM134_Output_Channel 2-2;
SG_MUL_VAL_ 2498695454 PDM134_Calib_time_DO02 PDM134_Output_Channel 2-2;
SG_MUL_VAL_ 2498695454 PDM134_Response_DO02 PDM134_Output_Channel 2-2;
SG_MUL_VAL_ 2498695454 PDM134_SS_Step_DO03 PDM134_Output_Channel 3-3;
SG_MUL_VAL_ 2498695454 PDM134_M_L_DO03 PDM134_Output_Channel 3-3;
SG_MUL_VAL_ 2498695454 PDM134_Loss_of_COMM_DO03 PDM134_Output_Channel 3-3;
SG_MUL_VAL_ 2498695454 PDM134_POR_command_DO03 PDM134_Output_Channel 3-3;
SG_MUL_VAL_ 2498695454 PDM134_POR_En_DO03 PDM134_Output_Channel 3-3;
SG_MUL_VAL_ 2498695454 PDM134_Command_type_DO03 PDM134_Output_Channel 3-3;
SG_MUL_VAL_ 2498695454 PDM134_Motor_braking_DO03 PDM134_Output_Channel 3-3;
SG_MUL_VAL_ 2498695454 PDM134_LSC_DO03 PDM134_Output_Channel 3-3;
SG_MUL_VAL_ 2498695454 PDM134_Calib_time_DO03 PDM134_Output_Channel 3-3;
SG_MUL_VAL_ 2498695454 PDM134_Response_DO03 PDM134_Output_Channel 3-3;
SG_MUL_VAL_ 2498695454 PDM134_SS_Step_DO04 PDM134_Output_Channel 4-4;
SG_MUL_VAL_ 2498695454 PDM134_M_L_DO04 PDM134_Output_Channel 4-4;
SG_MUL_VAL_ 2498695454 PDM134_Loss_of_COMM_DO04 PDM134_Output_Channel 4-4;
SG_MUL_VAL_ 2498695454 PDM134_POR_command_DO04 PDM134_Output_Channel 4-4;
SG_MUL_VAL_ 2498695454 PDM134_POR_En_DO04 PDM134_Output_Channel 4-4;
SG_MUL_VAL_ 2498695454 PDM134_Command_type_DO04 PDM134_Output_Channel 4-4;
SG_MUL_VAL_ 2498695454 PDM134_Motor_braking_DO04 PDM134_Output_Channel 4-4;
SG_MUL_VAL_ 2498695454 PDM134_LSC_DO04 PDM134_Output_Channel 4-4;
SG_MUL_VAL_ 2498695454 PDM134_Calib_time_DO04 PDM134_Output_Channel 4-4;
SG_MUL_VAL_ 2498695454 PDM134_Response_DO04 PDM134_Output_Channel 4-4;
SG_MUL_VAL_ 2498695454 PDM134_SS_Step_DO05 PDM134_Output_Channel 5-5;
SG_MUL_VAL_ 2498695454 PDM134_M_L_DO05 PDM134_Output_Channel 5-5;
SG_MUL_VAL_ 2498695454 PDM134_Loss_of_COMM_DO05 PDM134_Output_Channel 5-5;
SG_MUL_VAL_ 2498695454 PDM134_POR_command_DO05 PDM134_Output_Channel 5-5;
SG_MUL_VAL_ 2498695454 PDM134_POR_En_DO05 PDM134_Output_Channel 5-5;
SG_MUL_VAL_ 2498695454 PDM134_Command_type_DO05 PDM134_Output_Channel 5-5;
SG_MUL_VAL_ 2498695454 PDM134_Motor_braking_DO05 PDM134_Output_Channel 5-5;
SG_MUL_VAL_ 2498695454 PDM134_LSC_DO05 PDM134_Output_Channel 5-5;
SG_MUL_VAL_ 2498695454 PDM134_Calib_time_DO05 PDM134_Output_Channel 5-5;
SG_MUL_VAL_ 2498695454 PDM134_Response_DO05 PDM134_Output_Channel 5-5;
SG_MUL_VAL_ 2498695454 PDM134_SS_Step_DO06 PDM134_Output_Channel 6-6;
SG_MUL_VAL_ 2498695454 PDM134_M_L_DO06 PDM134_Output_Channel 6-6;
SG_MUL_VAL_ 2498695454 PDM134_Loss_of_COMM_DO06 PDM134_Output_Channel 6-6;
SG_MUL_VAL_ 2498695454 PDM134_POR_command_DO06 PDM134_Output_Channel 6-6;
SG_MUL_VAL_ 2498695454 PDM134_POR_En_DO06 PDM134_Output_Channel 6-6;
SG_MUL_VAL_ 2498695454 PDM134_Command_type_DO06 PDM134_Output_Channel 6-6;
SG_MUL_VAL_ 2498695454 PDM134_Motor_braking_DO06 PDM134_Output_Channel 6-6;
SG_MUL_VAL_ 2498695454 PDM134_LSC_DO06 PDM134_Output_Channel 6-6;
SG_MUL_VAL_ 2498695454 PDM134_Calib_time_DO06 PDM134_Output_Channel 6-6;
SG_MUL_VAL_ 2498695454 PDM134_Response_DO06 PDM134_Output_Channel 6-6;
SG_MUL_VAL_ 2498695454 PDM134_SS_Step_DO07 PDM134_Output_Channel 7-7;
SG_MUL_VAL_ 2498695454 PDM134_M_L_DO07 PDM134_Output_Channel 7-7;
SG_MUL_VAL_ 2498695454 PDM134_Loss_of_COMM_DO07 PDM134_Output_Channel 7-7;
SG_MUL_VAL_ 2498695454 PDM134_POR_command_DO07 PDM134_Output_Channel 7-7;
SG_MUL_VAL_ 2498695454 PDM134_POR_En_DO07 PDM134_Output_Channel 7-7;
SG_MUL_VAL_ 2498695454 PDM134_Command_type_DO07 PDM134_Output_Channel 7-7;
SG_MUL_VAL_ 2498695454 PDM134_Motor_braking_DO07 PDM134_Output_Channel 7-7;
SG_MUL_VAL_ 2498695454 PDM134_LSC_DO07 PDM134_Output_Channel 7-7;
SG_MUL_VAL_ 2498695454 PDM134_Calib_time_DO07 PDM134_Output_Channel 7-7;
SG_MUL_VAL_ 2498695454 PDM134_Response_DO07 PDM134_Output_Channel 7-7;
SG_MUL_VAL_ 2498695454 PDM134_SS_Step_DO08 PDM134_Output_Channel 8-8;
SG_MUL_VAL_ 2498695454 PDM134_M_L_DO08 PDM134_Output_Channel 8-8;
SG_MUL_VAL_ 2498695454 PDM134_Loss_of_COMM_DO08 PDM134_Output_Channel 8-8;
SG_MUL_VAL_ 2498695454 PDM134_POR_command_DO08 PDM134_Output_Channel 8-8;
SG_MUL_VAL_ 2498695454 PDM134_POR_En_DO08 PDM134_Output_Channel 8-8;
SG_MUL_VAL_ 2498695454 PDM134_Command_type_DO08 PDM134_Output_Channel 8-8;
SG_MUL_VAL_ 2498695454 PDM134_Motor_braking_DO08 PDM134_Output_Channel 8-8;
SG_MUL_VAL_ 2498695454 PDM134_LSC_DO08 PDM134_Output_Channel 8-8;
SG_MUL_VAL_ 2498695454 PDM134_Calib_time_DO08 PDM134_Output_Channel 8-8;
SG_MUL_VAL_ 2498695454 PDM134_Response_DO08 PDM134_Output_Channel 8-8;
SG_MUL_VAL_ 2498695454 PDM134_SS_Step_DO09 PDM134_Output_Channel 9-9;
SG_MUL_VAL_ 2498695454 PDM134_M_L_DO09 PDM134_Output_Channel 9-9;
SG_MUL_VAL_ 2498695454 PDM134_Loss_of_COMM_DO09 PDM134_Output_Channel 9-9;
SG_MUL_VAL_ 2498695454 PDM134_POR_command_DO09 PDM134_Output_Channel 9-9;
SG_MUL_VAL_ 2498695454 PDM134_POR_En_DO09 PDM134_Output_Channel 9-9;
SG_MUL_VAL_ 2498695454 PDM134_Command_type_DO09 PDM134_Output_Channel 9-9;
SG_MUL_VAL_ 2498695454 PDM134_Motor_braking_DO09 PDM134_Output_Channel 9-9;
SG_MUL_VAL_ 2498695454 PDM134_LSC_DO09 PDM134_Output_Channel 9-9;
SG_MUL_VAL_ 2498695454 PDM134_Calib_time_DO09 PDM134_Output_Channel 9-9;
SG_MUL_VAL_ 2498695454 PDM134_Response_DO09 PDM134_Output_Channel 9-9;
SG_MUL_VAL_ 2498695454 PDM134_SS_Step_DO10 PDM134_Output_Channel 10-10;
SG_MUL_VAL_ 2498695454 PDM134_M_L_DO10 PDM134_Output_Channel 10-10;
SG_MUL_VAL_ 2498695454 PDM134_Loss_of_COMM_DO10 PDM134_Output_Channel 10-10;
SG_MUL_VAL_ 2498695454 PDM134_POR_command_DO10 PDM134_Output_Channel 10-10;
SG_MUL_VAL_ 2498695454 PDM134_POR_En_DO10 PDM134_Output_Channel 10-10;
SG_MUL_VAL_ 2498695454 PDM134_Command_type_DO10 PDM134_Output_Channel 10-10;
SG_MUL_VAL_ 2498695454 PDM134_Motor_braking_DO10 PDM134_Output_Channel 10-10;
SG_MUL_VAL_ 2498695454 PDM134_LSC_DO10 PDM134_Output_Channel 10-10;
SG_MUL_VAL_ 2498695454 PDM134_Calib_time_DO10 PDM134_Output_Channel 10-10;
SG_MUL_VAL_ 2498695454 PDM134_Response_DO10 PDM134_Output_Channel 10-10;
SG_MUL_VAL_ 2498695454 PDM134_SS_Step_DO11 PDM134_Output_Channel 11-11;
SG_MUL_VAL_ 2498695454 PDM134_M_L_DO11 PDM134_Output_Channel 11-11;
SG_MUL_VAL_ 2498695454 PDM134_Loss_of_COMM_DO11 PDM134_Output_Channel 11-11;
SG_MUL_VAL_ 2498695454 PDM134_POR_command_DO11 PDM134_Output_Channel 11-11;
SG_MUL_VAL_ 2498695454 PDM134_POR_En_DO11 PDM134_Output_Channel 11-11;
SG_MUL_VAL_ 2498695454 PDM134_Command_type_DO11 PDM134_Output_Channel 11-11;
SG_MUL_VAL_ 2498695454 PDM134_Motor_braking_DO11 PDM134_Output_Channel 11-11;
SG_MUL_VAL_ 2498695454 PDM134_LSC_DO11 PDM134_Output_Channel 11-11;
SG_MUL_VAL_ 2498695454 PDM134_Calib_time_DO11 PDM134_Output_Channel 11-11;
SG_MUL_VAL_ 2498695454 PDM134_Response_DO11 PDM134_Output_Channel 11-11;
SG_MUL_VAL_ 2498695454 PDM134_SS_Step_DO12 PDM134_Output_Channel 12-12;
SG_MUL_VAL_ 2498695454 PDM134_M_L_DO12 PDM134_Output_Channel 12-12;
SG_MUL_VAL_ 2498695454 PDM134_Loss_of_COMM_DO12 PDM134_Output_Channel 12-12;
SG_MUL_VAL_ 2498695454 PDM134_POR_command_DO12 PDM134_Output_Channel 12-12;
SG_MUL_VAL_ 2498695454 PDM134_POR_En_DO12 PDM134_Output_Channel 12-12;
SG_MUL_VAL_ 2498695454 PDM134_Command_type_DO12 PDM134_Output_Channel 12-12;
SG_MUL_VAL_ 2498695454 PDM134_Motor_braking_DO12 PDM134_Output_Channel 12-12;
SG_MUL_VAL_ 2498695454 PDM134_LSC_DO12 PDM134_Output_Channel 12-12;
SG_MUL_VAL_ 2498695454 PDM134_Calib_time_DO12 PDM134_Output_Channel 12-12;
SG_MUL_VAL_ 2498695454 PDM134_Response_DO12 PDM134_Output_Channel 12-12;
SG_MUL_VAL_ 2498695454 PDM135_CL_A_DO01 PDM_MULTIP_0 135-135;
SG_MUL_VAL_ 2498695454 PDM135_Fb_type_DO01 PDM_MULTIP_0 135-135;
SG_MUL_VAL_ 2498695454 PDM135_Auto_reset_DO01 PDM_MULTIP_0 135-135;
SG_MUL_VAL_ 2498695454 PDM135_HS_HB_DO01 PDM_MULTIP_0 135-135;
SG_MUL_VAL_ 2498695454 PDM135_CL_A_DO02 PDM_MULTIP_0 135-135;
SG_MUL_VAL_ 2498695454 PDM135_Fb_type_DO02 PDM_MULTIP_0 135-135;
SG_MUL_VAL_ 2498695454 PDM135_Auto_reset_DO02 PDM_MULTIP_0 135-135;
SG_MUL_VAL_ 2498695454 PDM135_HS_HB_DO02 PDM_MULTIP_0 135-135;
SG_MUL_VAL_ 2498695454 PDM135_CL_A_DO03 PDM_MULTIP_0 135-135;
SG_MUL_VAL_ 2498695454 PDM135_Fb_type_DO03 PDM_MULTIP_0 135-135;
SG_MUL_VAL_ 2498695454 PDM135_Auto_reset_DO03 PDM_MULTIP_0 135-135;
SG_MUL_VAL_ 2498695454 PDM135_HS_HB_DO03 PDM_MULTIP_0 135-135;
SG_MUL_VAL_ 2498695454 PDM135_CL_A_DO04 PDM_MULTIP_0 135-135;
SG_MUL_VAL_ 2498695454 PDM135_Fb_type_DO04 PDM_MULTIP_0 135-135;
SG_MUL_VAL_ 2498695454 PDM135_Auto_reset_DO04 PDM_MULTIP_0 135-135;
SG_MUL_VAL_ 2498695454 PDM135_HS_HB_DO04 PDM_MULTIP_0 135-135;
SG_MUL_VAL_ 2498695454 PDM135_CL_A_DO05 PDM_MULTIP_0 135-135;
SG_MUL_VAL_ 2498695454 PDM135_Fb_type_DO05 PDM_MULTIP_0 135-135;
SG_MUL_VAL_ 2498695454 PDM135_Auto_reset_DO05 PDM_MULTIP_0 135-135;
SG_MUL_VAL_ 2498695454 PDM135_HS_HB_DO05 PDM_MULTIP_0 135-135;
SG_MUL_VAL_ 2498695454 PDM135_CL_A_DO06 PDM_MULTIP_0 135-135;
SG_MUL_VAL_ 2498695454 PDM135_Fb_type_DO06 PDM_MULTIP_0 135-135;
SG_MUL_VAL_ 2498695454 PDM135_Auto_reset_DO06 PDM_MULTIP_0 135-135;
SG_MUL_VAL_ 2498695454 PDM135_HS_HB_DO06 PDM_MULTIP_0 135-135;
SG_MUL_VAL_ 2498695454 PDM135_reserved_135 PDM_MULTIP_0 135-135;
SG_MUL_VAL_ 2498695454 PDM136_CL_A_DO07 PDM_MULTIP_0 136-136;
SG_MUL_VAL_ 2498695454 PDM136_Fb_type_DO07 PDM_MULTIP_0 136-136;
SG_MUL_VAL_ 2498695454 PDM136_Auto_reset_DO07 PDM_MULTIP_0 136-136;
SG_MUL_VAL_ 2498695454 PDM136_HS_HB_DO07 PDM_MULTIP_0 136-136;
SG_MUL_VAL_ 2498695454 PDM136_CL_A_DO08 PDM_MULTIP_0 136-136;
SG_MUL_VAL_ 2498695454 PDM136_Fb_type_DO08 PDM_MULTIP_0 136-136;
SG_MUL_VAL_ 2498695454 PDM136_Auto_reset_DO08 PDM_MULTIP_0 136-136;
SG_MUL_VAL_ 2498695454 PDM136_HS_HB_DO08 PDM_MULTIP_0 136-136;
SG_MUL_VAL_ 2498695454 PDM136_CL_A_DO09 PDM_MULTIP_0 136-136;
SG_MUL_VAL_ 2498695454 PDM136_Fb_type_DO09 PDM_MULTIP_0 136-136;
SG_MUL_VAL_ 2498695454 PDM136_Auto_reset_DO09 PDM_MULTIP_0 136-136;
SG_MUL_VAL_ 2498695454 PDM136_HS_HB_DO09 PDM_MULTIP_0 136-136;
SG_MUL_VAL_ 2498695454 PDM136_CL_A_DO10 PDM_MULTIP_0 136-136;
SG_MUL_VAL_ 2498695454 PDM136_Fb_type_DO10 PDM_MULTIP_0 136-136;
SG_MUL_VAL_ 2498695454 PDM136_Auto_reset_DO10 PDM_MULTIP_0 136-136;
SG_MUL_VAL_ 2498695454 PDM136_HS_HB_DO10 PDM_MULTIP_0 136-136;
SG_MUL_VAL_ 2498695454 PDM136_CL_A_DO11 PDM_MULTIP_0 136-136;
SG_MUL_VAL_ 2498695454 PDM136_Fb_type_DO11 PDM_MULTIP_0 136-136;
SG_MUL_VAL_ 2498695454 PDM136_Auto_reset_DO11 PDM_MULTIP_0 136-136;
SG_MUL_VAL_ 2498695454 PDM136_HS_HB_DO11 PDM_MULTIP_0 136-136;
SG_MUL_VAL_ 2498695454 PDM136_CL_A_DO12 PDM_MULTIP_0 136-136;
SG_MUL_VAL_ 2498695454 PDM136_Fb_type_DO12 PDM_MULTIP_0 136-136;
SG_MUL_VAL_ 2498695454 PDM136_Auto_reset_DO12 PDM_MULTIP_0 136-136;
SG_MUL_VAL_ 2498695454 PDM136_HS_HB_DO12 PDM_MULTIP_0 136-136;
SG_MUL_VAL_ 2498695454 PDM136_reserved_136 PDM_MULTIP_0 136-136;
